AUTOSAR XML (schema 00046)
package /MICROSAR/NvM_swc/DataTypes
  impl type NvM_RequestResultType: compu {0=NVM_REQ_OK, 1=NVM_REQ_NOT_OK, 2=NVM_REQ_PENDING, 3=NVM_REQ_INTEGRITY_FAILED, 4=NVM_REQ_BLOCK_SKIPPED, 5=NVM_REQ_NV_INVALIDATED, 6=NVM_REQ_CANCELED, 7=NVM_REQ_REDUNDANCY_FAILED, 8=NVM_REQ_RESTORED_FROM_ROM}, range raw 0..8, implementation-data-type=uint8
  impl type NvM_BlockIdType: range raw 1..32767, implementation-data-type=uint16
  impl type NvM_ServiceIdType: compu {6=NVM_READ_BLOCK, 7=NVM_WRITE_BLOCK, 8=NVM_RESTORE_BLOCK_DEFAULTS, 9=NVM_ERASE_BLOCK, 11=NVM_INVALIDATE_NV_BLOCK, 12=NVM_READ_ALL}, range raw 6..12, implementation-data-type=uint8
package /MICROSAR/NvM_swc/Interfaces
  client server interface NvMAdministration: is-service=true, service-kind=NON-VOLATILE-RAM-MANAGER
    operation SetBlockProtection: possible-error=NvMAdministration/E_NOT_OK
      arg ProtectionEnabled: type=boolean, direction=IN
    error E_NOT_OK: error-code=1
  client server interface NvMService_AC3_SRBS_Defs: is-service=true, service-kind=NON-VOLATILE-RAM-MANAGER
    7 x operation, all with possible-error=NvMService_AC3_SRBS_Defs/E_NOT_OK:
      GetErrorStatus
        arg ErrorStatus: type=NvM_RequestResultType, direction=OUT
      SetRamBlockStatus
        arg RamBlockStatus: type=boolean, direction=IN
      ReadBlock
        arg DstPtr: type=dtRef_VOID, direction=IN
      WriteBlock
        arg SrcPtr: type=dtRef_const_VOID, direction=IN
      RestoreBlockDefaults
        arg DstPtr: type=dtRef_VOID, direction=IN
      InvalidateNvBlock
      EraseBlock
    error E_NOT_OK: error-code=1
  client server interface NvMNotifyJobFinished: is-service=true, service-kind=NON-VOLATILE-RAM-MANAGER
    operation JobFinished
      arg ServiceId: type=NvM_ServiceIdType, direction=IN
      arg JobResult: type=NvM_RequestResultType, direction=IN
package /MICROSAR/NvM_swc/ComponentTypes
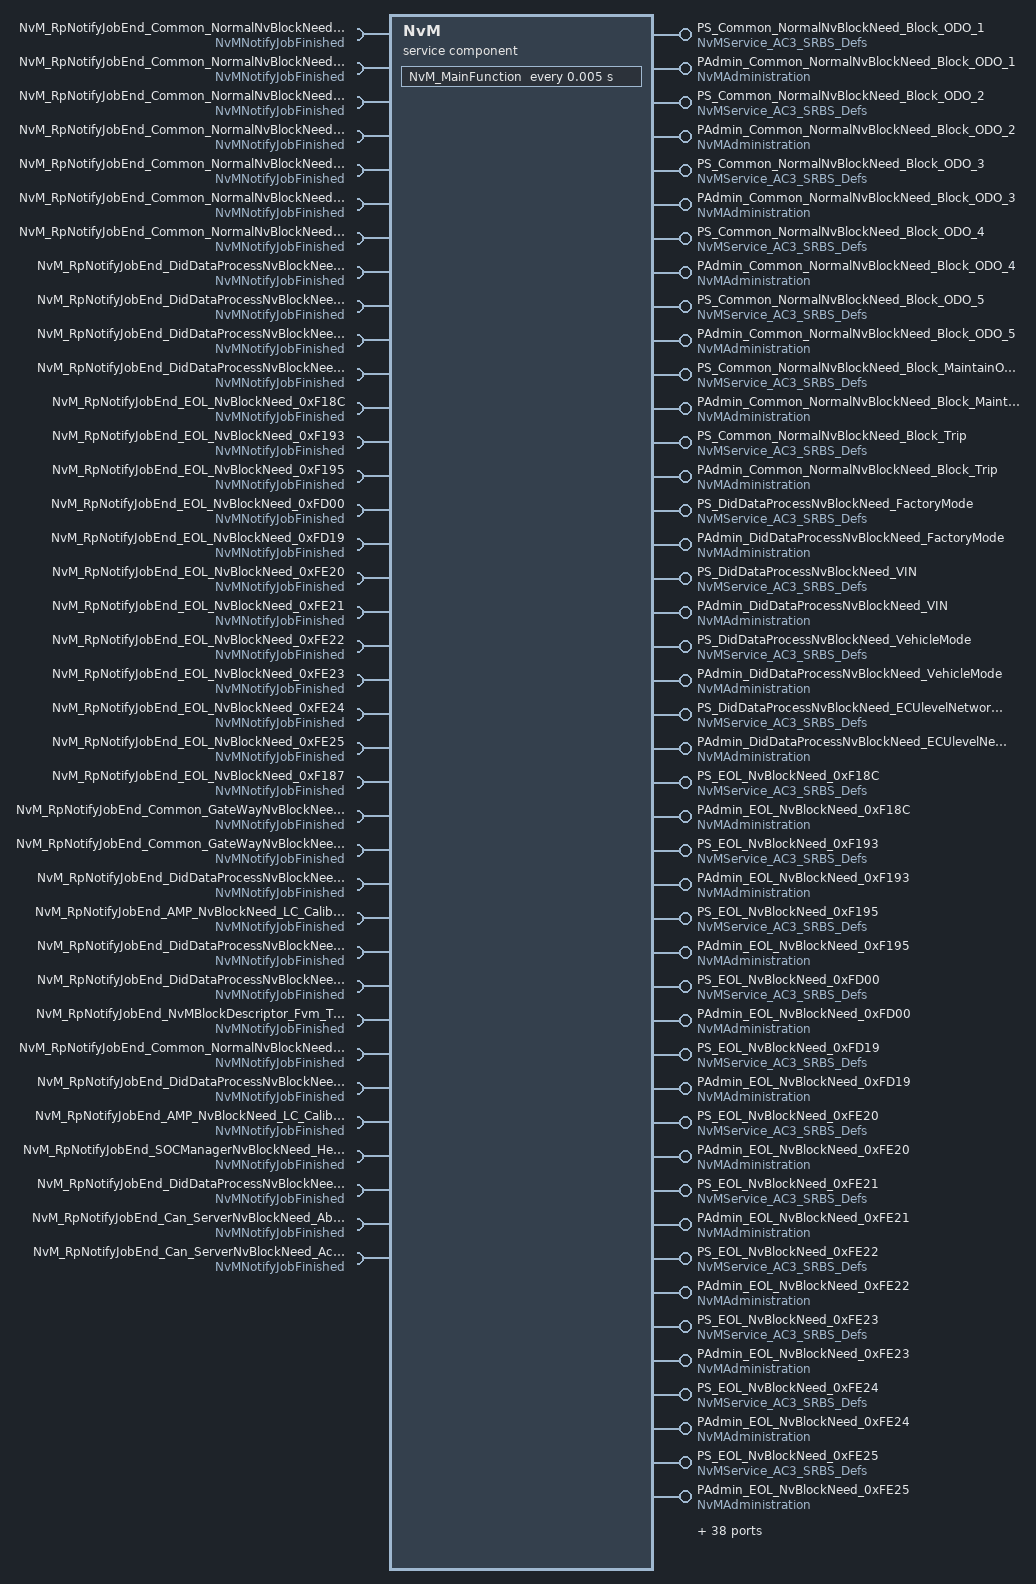
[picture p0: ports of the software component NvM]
  service sw component type NvM: category=SERVICE_COMPONENT
    provide port PS_Common_NormalNvBlockNeed_Block_ODO_1: provided-interface=NvMService_AC3_SRBS_Defs
    provide port PAdmin_Common_NormalNvBlockNeed_Block_ODO_1: provided-interface=NvMAdministration
    require port NvM_RpNotifyJobEnd_Common_NormalNvBlockNeed_Block_ODO_1: required-interface=NvMNotifyJobFinished
    provide port PS_Common_NormalNvBlockNeed_Block_ODO_2: provided-interface=NvMService_AC3_SRBS_Defs
    provide port PAdmin_Common_NormalNvBlockNeed_Block_ODO_2: provided-interface=NvMAdministration
    require port NvM_RpNotifyJobEnd_Common_NormalNvBlockNeed_Block_ODO_2: required-interface=NvMNotifyJobFinished
    provide port PS_Common_NormalNvBlockNeed_Block_ODO_3: provided-interface=NvMService_AC3_SRBS_Defs
    provide port PAdmin_Common_NormalNvBlockNeed_Block_ODO_3: provided-interface=NvMAdministration
    require port NvM_RpNotifyJobEnd_Common_NormalNvBlockNeed_Block_ODO_3: required-interface=NvMNotifyJobFinished
    provide port PS_Common_NormalNvBlockNeed_Block_ODO_4: provided-interface=NvMService_AC3_SRBS_Defs
    provide port PAdmin_Common_NormalNvBlockNeed_Block_ODO_4: provided-interface=NvMAdministration
    require port NvM_RpNotifyJobEnd_Common_NormalNvBlockNeed_Block_ODO_4: required-interface=NvMNotifyJobFinished
    provide port PS_Common_NormalNvBlockNeed_Block_ODO_5: provided-interface=NvMService_AC3_SRBS_Defs
    provide port PAdmin_Common_NormalNvBlockNeed_Block_ODO_5: provided-interface=NvMAdministration
    require port NvM_RpNotifyJobEnd_Common_NormalNvBlockNeed_Block_ODO_5: required-interface=NvMNotifyJobFinished
    provide port PS_Common_NormalNvBlockNeed_Block_MaintainOdo: provided-interface=NvMService_AC3_SRBS_Defs
    provide port PAdmin_Common_NormalNvBlockNeed_Block_MaintainOdo: provided-interface=NvMAdministration
    require port NvM_RpNotifyJobEnd_Common_NormalNvBlockNeed_Block_MaintainOdo: required-interface=NvMNotifyJobFinished
    provide port PS_Common_NormalNvBlockNeed_Block_Trip: provided-interface=NvMService_AC3_SRBS_Defs
    provide port PAdmin_Common_NormalNvBlockNeed_Block_Trip: provided-interface=NvMAdministration
    require port NvM_RpNotifyJobEnd_Common_NormalNvBlockNeed_Block_Trip: required-interface=NvMNotifyJobFinished
    provide port PS_DidDataProcessNvBlockNeed_FactoryMode: provided-interface=NvMService_AC3_SRBS_Defs
    provide port PAdmin_DidDataProcessNvBlockNeed_FactoryMode: provided-interface=NvMAdministration
    require port NvM_RpNotifyJobEnd_DidDataProcessNvBlockNeed_FactoryMode: required-interface=NvMNotifyJobFinished
    provide port PS_DidDataProcessNvBlockNeed_VIN: provided-interface=NvMService_AC3_SRBS_Defs
    provide port PAdmin_DidDataProcessNvBlockNeed_VIN: provided-interface=NvMAdministration
    require port NvM_RpNotifyJobEnd_DidDataProcessNvBlockNeed_VIN: required-interface=NvMNotifyJobFinished
    provide port PS_DidDataProcessNvBlockNeed_VehicleMode: provided-interface=NvMService_AC3_SRBS_Defs
    provide port PAdmin_DidDataProcessNvBlockNeed_VehicleMode: provided-interface=NvMAdministration
    require port NvM_RpNotifyJobEnd_DidDataProcessNvBlockNeed_VehicleMode: required-interface=NvMNotifyJobFinished
    provide port PS_DidDataProcessNvBlockNeed_ECUlevelNetworkConfigurationData: provided-interface=NvMService_AC3_SRBS_Defs
    provide port PAdmin_DidDataProcessNvBlockNeed_ECUlevelNetworkConfigurationData: provided-interface=NvMAdministration
    require port NvM_RpNotifyJobEnd_DidDataProcessNvBlockNeed_ECUlevelNetworkConfigurationData: required-interface=NvMNotifyJobFinished
    provide port PS_EOL_NvBlockNeed_0xF18C: provided-interface=NvMService_AC3_SRBS_Defs
    provide port PAdmin_EOL_NvBlockNeed_0xF18C: provided-interface=NvMAdministration
    require port NvM_RpNotifyJobEnd_EOL_NvBlockNeed_0xF18C: required-interface=NvMNotifyJobFinished
    provide port PS_EOL_NvBlockNeed_0xF193: provided-interface=NvMService_AC3_SRBS_Defs
    provide port PAdmin_EOL_NvBlockNeed_0xF193: provided-interface=NvMAdministration
    require port NvM_RpNotifyJobEnd_EOL_NvBlockNeed_0xF193: required-interface=NvMNotifyJobFinished
    provide port PS_EOL_NvBlockNeed_0xF195: provided-interface=NvMService_AC3_SRBS_Defs
    provide port PAdmin_EOL_NvBlockNeed_0xF195: provided-interface=NvMAdministration
    require port NvM_RpNotifyJobEnd_EOL_NvBlockNeed_0xF195: required-interface=NvMNotifyJobFinished
    provide port PS_EOL_NvBlockNeed_0xFD00: provided-interface=NvMService_AC3_SRBS_Defs
    provide port PAdmin_EOL_NvBlockNeed_0xFD00: provided-interface=NvMAdministration
    require port NvM_RpNotifyJobEnd_EOL_NvBlockNeed_0xFD00: required-interface=NvMNotifyJobFinished
    provide port PS_EOL_NvBlockNeed_0xFD19: provided-interface=NvMService_AC3_SRBS_Defs
    provide port PAdmin_EOL_NvBlockNeed_0xFD19: provided-interface=NvMAdministration
    require port NvM_RpNotifyJobEnd_EOL_NvBlockNeed_0xFD19: required-interface=NvMNotifyJobFinished
    provide port PS_EOL_NvBlockNeed_0xFE20: provided-interface=NvMService_AC3_SRBS_Defs
    provide port PAdmin_EOL_NvBlockNeed_0xFE20: provided-interface=NvMAdministration
    require port NvM_RpNotifyJobEnd_EOL_NvBlockNeed_0xFE20: required-interface=NvMNotifyJobFinished
    provide port PS_EOL_NvBlockNeed_0xFE21: provided-interface=NvMService_AC3_SRBS_Defs
    provide port PAdmin_EOL_NvBlockNeed_0xFE21: provided-interface=NvMAdministration
    require port NvM_RpNotifyJobEnd_EOL_NvBlockNeed_0xFE21: required-interface=NvMNotifyJobFinished
    provide port PS_EOL_NvBlockNeed_0xFE22: provided-interface=NvMService_AC3_SRBS_Defs
    provide port PAdmin_EOL_NvBlockNeed_0xFE22: provided-interface=NvMAdministration
    require port NvM_RpNotifyJobEnd_EOL_NvBlockNeed_0xFE22: required-interface=NvMNotifyJobFinished
    provide port PS_EOL_NvBlockNeed_0xFE23: provided-interface=NvMService_AC3_SRBS_Defs
    provide port PAdmin_EOL_NvBlockNeed_0xFE23: provided-interface=NvMAdministration
    require port NvM_RpNotifyJobEnd_EOL_NvBlockNeed_0xFE23: required-interface=NvMNotifyJobFinished
    provide port PS_EOL_NvBlockNeed_0xFE24: provided-interface=NvMService_AC3_SRBS_Defs
    provide port PAdmin_EOL_NvBlockNeed_0xFE24: provided-interface=NvMAdministration
    require port NvM_RpNotifyJobEnd_EOL_NvBlockNeed_0xFE24: required-interface=NvMNotifyJobFinished
    provide port PS_EOL_NvBlockNeed_0xFE25: provided-interface=NvMService_AC3_SRBS_Defs
    provide port PAdmin_EOL_NvBlockNeed_0xFE25: provided-interface=NvMAdministration
    require port NvM_RpNotifyJobEnd_EOL_NvBlockNeed_0xFE25: required-interface=NvMNotifyJobFinished
    provide port PS_EOL_NvBlockNeed_0xF187: provided-interface=NvMService_AC3_SRBS_Defs
    provide port PAdmin_EOL_NvBlockNeed_0xF187: provided-interface=NvMAdministration
    require port NvM_RpNotifyJobEnd_EOL_NvBlockNeed_0xF187: required-interface=NvMNotifyJobFinished
    provide port PS_Common_GateWayNvBlockNeed_Block_IPC_Config_Data: provided-interface=NvMService_AC3_SRBS_Defs
    provide port PAdmin_Common_GateWayNvBlockNeed_Block_IPC_Config_Data: provided-interface=NvMAdministration
    require port NvM_RpNotifyJobEnd_Common_GateWayNvBlockNeed_Block_IPC_Config_Data: required-interface=NvMNotifyJobFinished
    provide port PS_Common_GateWayNvBlockNeed_Block_IPC_CAN_Data: provided-interface=NvMService_AC3_SRBS_Defs
    provide port PAdmin_Common_GateWayNvBlockNeed_Block_IPC_CAN_Data: provided-interface=NvMAdministration
    require port NvM_RpNotifyJobEnd_Common_GateWayNvBlockNeed_Block_IPC_CAN_Data: required-interface=NvMNotifyJobFinished
    8 x provide port:
      PS_MiscNvBlockNeed_ResetInfomation: provided-interface=NvMService_AC3_SRBS_Defs
      PAdmin_MiscNvBlockNeed_ResetInfomation: provided-interface=NvMAdministration
      PS_DCM_ServerNvBlockNeedSecAttemptCount: provided-interface=NvMService_AC3_SRBS_Defs
      PAdmin_DCM_ServerNvBlockNeedSecAttemptCount: provided-interface=NvMAdministration
      PS_DCM_ServerNvBlockNeed_EOLUnlockCnt: provided-interface=NvMService_AC3_SRBS_Defs
      PAdmin_DCM_ServerNvBlockNeed_EOLUnlockCnt: provided-interface=NvMAdministration
      PS_DidDataProcessNvBlockNeed_ClusterInternalConfiguration: provided-interface=NvMService_AC3_SRBS_Defs
      PAdmin_DidDataProcessNvBlockNeed_ClusterInternalConfiguration: provided-interface=NvMAdministration
    require port NvM_RpNotifyJobEnd_DidDataProcessNvBlockNeed_ClusterInternalConfiguration: required-interface=NvMNotifyJobFinished
    provide port PS_AMP_NvBlockNeed_LC_Calibration: provided-interface=NvMService_AC3_SRBS_Defs
    provide port PAdmin_AMP_NvBlockNeed_LC_Calibration: provided-interface=NvMAdministration
    require port NvM_RpNotifyJobEnd_AMP_NvBlockNeed_LC_Calibration: required-interface=NvMNotifyJobFinished
    provide port PS_DidDataProcessNvBlockNeed_E2ESwitch: provided-interface=NvMService_AC3_SRBS_Defs
    provide port PAdmin_DidDataProcessNvBlockNeed_E2ESwitch: provided-interface=NvMAdministration
    require port NvM_RpNotifyJobEnd_DidDataProcessNvBlockNeed_E2ESwitch: required-interface=NvMNotifyJobFinished
    provide port PS_DidDataProcessNvBlockNeed_SecOcSwitch: provided-interface=NvMService_AC3_SRBS_Defs
    provide port PAdmin_DidDataProcessNvBlockNeed_SecOcSwitch: provided-interface=NvMAdministration
    require port NvM_RpNotifyJobEnd_DidDataProcessNvBlockNeed_SecOcSwitch: required-interface=NvMNotifyJobFinished
    4 x provide port:
      PS_NvBlockNeed_UpgradeResetFlag: provided-interface=NvMService_AC3_SRBS_Defs
      PAdmin_NvBlockNeed_UpgradeResetFlag: provided-interface=NvMAdministration
      PS_NvMBlockDescriptor_Fvm_TripCount: provided-interface=NvMService_AC3_SRBS_Defs
      PAdmin_NvMBlockDescriptor_Fvm_TripCount: provided-interface=NvMAdministration
    require port NvM_RpNotifyJobEnd_NvMBlockDescriptor_Fvm_TripCount: required-interface=NvMNotifyJobFinished
    provide port PS_Common_NormalNvBlockNeed_Menu: provided-interface=NvMService_AC3_SRBS_Defs
    provide port PAdmin_Common_NormalNvBlockNeed_Menu: provided-interface=NvMAdministration
    require port NvM_RpNotifyJobEnd_Common_NormalNvBlockNeed_Menu: required-interface=NvMNotifyJobFinished
    provide port PS_DidDataProcessNvBlockNeed_VehicleSoftwareVersion: provided-interface=NvMService_AC3_SRBS_Defs
    provide port PAdmin_DidDataProcessNvBlockNeed_VehicleSoftwareVersion: provided-interface=NvMAdministration
    require port NvM_RpNotifyJobEnd_DidDataProcessNvBlockNeed_VehicleSoftwareVersion: required-interface=NvMNotifyJobFinished
    provide port PS_AMP_NvBlockNeed_LC_Calibration2: provided-interface=NvMService_AC3_SRBS_Defs
    provide port PAdmin_AMP_NvBlockNeed_LC_Calibration2: provided-interface=NvMAdministration
    require port NvM_RpNotifyJobEnd_AMP_NvBlockNeed_LC_Calibration2: required-interface=NvMNotifyJobFinished
    provide port PS_SOCManagerNvBlockNeed_HealthSwitch: provided-interface=NvMService_AC3_SRBS_Defs
    provide port PAdmin_SOCManagerNvBlockNeed_HealthSwitch: provided-interface=NvMAdministration
    require port NvM_RpNotifyJobEnd_SOCManagerNvBlockNeed_HealthSwitch: required-interface=NvMNotifyJobFinished
    provide port PS_DidDataProcessNvBlockNeed_ClusterDisplayHMIAdjustmentOffset: provided-interface=NvMService_AC3_SRBS_Defs
    provide port PAdmin_DidDataProcessNvBlockNeed_ClusterDisplayHMIAdjustmentOffset: provided-interface=NvMAdministration
    require port NvM_RpNotifyJobEnd_DidDataProcessNvBlockNeed_ClusterDisplayHMIAdjustmentOffset: required-interface=NvMNotifyJobFinished
    provide port PS_Can_ServerNvBlockNeed_AbnormalWakeupSleepRecords: provided-interface=NvMService_AC3_SRBS_Defs
    provide port PAdmin_Can_ServerNvBlockNeed_AbnormalWakeupSleepRecords: provided-interface=NvMAdministration
    require port NvM_RpNotifyJobEnd_Can_ServerNvBlockNeed_AbnormalWakeupSleepRecords: required-interface=NvMNotifyJobFinished
    provide port PS_Can_ServerNvBlockNeed_ActiveWUCounter: provided-interface=NvMService_AC3_SRBS_Defs
    provide port PAdmin_Can_ServerNvBlockNeed_ActiveWUCounter: provided-interface=NvMAdministration
    require port NvM_RpNotifyJobEnd_Can_ServerNvBlockNeed_ActiveWUCounter: required-interface=NvMNotifyJobFinished
    behavior NvMInternalBehavior: handle-termination-and-restart=NO-SUPPORT
      timing event Timer_NvM_MainFunction: start-on-event=NvM_MainFunction, period=0.005
      328 x operation invoked event:
        OpEventGetErrorStatus_GetErrorStatus_PS_Common_NormalNvBlockNeed_Block_ODO_{1..5}: start-on-event=GetErrorStatus, operation=PS_Common_NormalNvBlockNeed_Block_ODO_{1..5}.GetErrorStatus
        OpEventGetErrorStatus_GetErrorStatus_PS_Common_NormalNvBlockNeed_Block_MaintainOdo: start-on-event=GetErrorStatus, operation=PS_Common_NormalNvBlockNeed_Block_MaintainOdo.GetErrorStatus
        OpEventGetErrorStatus_GetErrorStatus_PS_Common_NormalNvBlockNeed_Block_Trip: start-on-event=GetErrorStatus, operation=PS_Common_NormalNvBlockNeed_Block_Trip.GetErrorStatus
        OpEventSetRamBlockStatus_SetRamBlockStatus_PS_Common_NormalNvBlockNeed_Block_ODO_{1..5}: start-on-event=SetRamBlockStatus, operation=PS_Common_NormalNvBlockNeed_Block_ODO_{1..5}.SetRamBlockStatus
        OpEventSetRamBlockStatus_SetRamBlockStatus_PS_Common_NormalNvBlockNeed_Block_MaintainOdo: start-on-event=SetRamBlockStatus, operation=PS_Common_NormalNvBlockNeed_Block_MaintainOdo.SetRamBlockStatus
        OpEventSetRamBlockStatus_SetRamBlockStatus_PS_Common_NormalNvBlockNeed_Block_Trip: start-on-event=SetRamBlockStatus, operation=PS_Common_NormalNvBlockNeed_Block_Trip.SetRamBlockStatus
        OpEventReadBlock_ReadBlock_PS_Common_NormalNvBlockNeed_Block_ODO_{1..5}: start-on-event=ReadBlock, operation=PS_Common_NormalNvBlockNeed_Block_ODO_{1..5}.ReadBlock
        OpEventReadBlock_ReadBlock_PS_Common_NormalNvBlockNeed_Block_MaintainOdo: start-on-event=ReadBlock, operation=PS_Common_NormalNvBlockNeed_Block_MaintainOdo.ReadBlock
        OpEventReadBlock_ReadBlock_PS_Common_NormalNvBlockNeed_Block_Trip: start-on-event=ReadBlock, operation=PS_Common_NormalNvBlockNeed_Block_Trip.ReadBlock
        OpEventWriteBlock_WriteBlock_PS_Common_NormalNvBlockNeed_Block_ODO_{1..5}: start-on-event=WriteBlock, operation=PS_Common_NormalNvBlockNeed_Block_ODO_{1..5}.WriteBlock
        OpEventWriteBlock_WriteBlock_PS_Common_NormalNvBlockNeed_Block_MaintainOdo: start-on-event=WriteBlock, operation=PS_Common_NormalNvBlockNeed_Block_MaintainOdo.WriteBlock
        OpEventWriteBlock_WriteBlock_PS_Common_NormalNvBlockNeed_Block_Trip: start-on-event=WriteBlock, operation=PS_Common_NormalNvBlockNeed_Block_Trip.WriteBlock
        OpEventRestoreBlockDefaults_RestoreBlockDefaults_PS_Common_NormalNvBlockNeed_Block_ODO_{1..5}: start-on-event=RestoreBlockDefaults, operation=PS_Common_NormalNvBlockNeed_Block_ODO_{1..5}.RestoreBlockDefaults
        OpEventRestoreBlockDefaults_RestoreBlockDefaults_PS_Common_NormalNvBlockNeed_Block_MaintainOdo: start-on-event=RestoreBlockDefaults, operation=PS_Common_NormalNvBlockNeed_Block_MaintainOdo.RestoreBlockDefaults
        OpEventRestoreBlockDefaults_RestoreBlockDefaults_PS_Common_NormalNvBlockNeed_Block_Trip: start-on-event=RestoreBlockDefaults, operation=PS_Common_NormalNvBlockNeed_Block_Trip.RestoreBlockDefaults
        OpEventInvalidateNvBlock_InvalidateNvBlock_PS_Common_NormalNvBlockNeed_Block_ODO_{1..5}: start-on-event=InvalidateNvBlock, operation=PS_Common_NormalNvBlockNeed_Block_ODO_{1..5}.InvalidateNvBlock
        OpEventInvalidateNvBlock_InvalidateNvBlock_PS_Common_NormalNvBlockNeed_Block_MaintainOdo: start-on-event=InvalidateNvBlock, operation=PS_Common_NormalNvBlockNeed_Block_MaintainOdo.InvalidateNvBlock
        OpEventInvalidateNvBlock_InvalidateNvBlock_PS_Common_NormalNvBlockNeed_Block_Trip: start-on-event=InvalidateNvBlock, operation=PS_Common_NormalNvBlockNeed_Block_Trip.InvalidateNvBlock
        OpEventEraseBlock_EraseBlock_PS_Common_NormalNvBlockNeed_Block_ODO_{1..5}: start-on-event=EraseBlock, operation=PS_Common_NormalNvBlockNeed_Block_ODO_{1..5}.EraseBlock
        OpEventEraseBlock_EraseBlock_PS_Common_NormalNvBlockNeed_Block_MaintainOdo: start-on-event=EraseBlock, operation=PS_Common_NormalNvBlockNeed_Block_MaintainOdo.EraseBlock
        OpEventEraseBlock_EraseBlock_PS_Common_NormalNvBlockNeed_Block_Trip: start-on-event=EraseBlock, operation=PS_Common_NormalNvBlockNeed_Block_Trip.EraseBlock
        OpEventSetBlockProtection_SetBlockProtection_PAdmin_Common_NormalNvBlockNeed_Block_ODO_{1..5}: start-on-event=SetBlockProtection, operation=PAdmin_Common_NormalNvBlockNeed_Block_ODO_{1..5}.SetBlockProtection
        OpEventSetBlockProtection_SetBlockProtection_PAdmin_Common_NormalNvBlockNeed_Block_MaintainOdo: start-on-event=SetBlockProtection, operation=PAdmin_Common_NormalNvBlockNeed_Block_MaintainOdo.SetBlockProtection
        OpEventSetBlockProtection_SetBlockProtection_PAdmin_Common_NormalNvBlockNeed_Block_Trip: start-on-event=SetBlockProtection, operation=PAdmin_Common_NormalNvBlockNeed_Block_Trip.SetBlockProtection
        OpEventGetErrorStatus_GetErrorStatus_PS_DidDataProcessNvBlockNeed_FactoryMode: start-on-event=GetErrorStatus, operation=PS_DidDataProcessNvBlockNeed_FactoryMode.GetErrorStatus
        OpEventGetErrorStatus_GetErrorStatus_PS_DidDataProcessNvBlockNeed_VIN: start-on-event=GetErrorStatus, operation=PS_DidDataProcessNvBlockNeed_VIN.GetErrorStatus
        OpEventGetErrorStatus_GetErrorStatus_PS_DidDataProcessNvBlockNeed_VehicleMode: start-on-event=GetErrorStatus, operation=PS_DidDataProcessNvBlockNeed_VehicleMode.GetErrorStatus
        OpEventSetRamBlockStatus_SetRamBlockStatus_PS_DidDataProcessNvBlockNeed_FactoryMode: start-on-event=SetRamBlockStatus, operation=PS_DidDataProcessNvBlockNeed_FactoryMode.SetRamBlockStatus
        OpEventSetRamBlockStatus_SetRamBlockStatus_PS_DidDataProcessNvBlockNeed_VIN: start-on-event=SetRamBlockStatus, operation=PS_DidDataProcessNvBlockNeed_VIN.SetRamBlockStatus
        OpEventSetRamBlockStatus_SetRamBlockStatus_PS_DidDataProcessNvBlockNeed_VehicleMode: start-on-event=SetRamBlockStatus, operation=PS_DidDataProcessNvBlockNeed_VehicleMode.SetRamBlockStatus
        OpEventReadBlock_ReadBlock_PS_DidDataProcessNvBlockNeed_FactoryMode: start-on-event=ReadBlock, operation=PS_DidDataProcessNvBlockNeed_FactoryMode.ReadBlock
        OpEventReadBlock_ReadBlock_PS_DidDataProcessNvBlockNeed_VIN: start-on-event=ReadBlock, operation=PS_DidDataProcessNvBlockNeed_VIN.ReadBlock
        OpEventReadBlock_ReadBlock_PS_DidDataProcessNvBlockNeed_VehicleMode: start-on-event=ReadBlock, operation=PS_DidDataProcessNvBlockNeed_VehicleMode.ReadBlock
        OpEventWriteBlock_WriteBlock_PS_DidDataProcessNvBlockNeed_FactoryMode: start-on-event=WriteBlock, operation=PS_DidDataProcessNvBlockNeed_FactoryMode.WriteBlock
        OpEventWriteBlock_WriteBlock_PS_DidDataProcessNvBlockNeed_VIN: start-on-event=WriteBlock, operation=PS_DidDataProcessNvBlockNeed_VIN.WriteBlock
        OpEventWriteBlock_WriteBlock_PS_DidDataProcessNvBlockNeed_VehicleMode: start-on-event=WriteBlock, operation=PS_DidDataProcessNvBlockNeed_VehicleMode.WriteBlock
        OpEventRestoreBlockDefaults_RestoreBlockDefaults_PS_DidDataProcessNvBlockNeed_FactoryMode: start-on-event=RestoreBlockDefaults, operation=PS_DidDataProcessNvBlockNeed_FactoryMode.RestoreBlockDefaults
        OpEventRestoreBlockDefaults_RestoreBlockDefaults_PS_DidDataProcessNvBlockNeed_VIN: start-on-event=RestoreBlockDefaults, operation=PS_DidDataProcessNvBlockNeed_VIN.RestoreBlockDefaults
        OpEventRestoreBlockDefaults_RestoreBlockDefaults_PS_DidDataProcessNvBlockNeed_VehicleMode: start-on-event=RestoreBlockDefaults, operation=PS_DidDataProcessNvBlockNeed_VehicleMode.RestoreBlockDefaults
        OpEventInvalidateNvBlock_InvalidateNvBlock_PS_DidDataProcessNvBlockNeed_FactoryMode: start-on-event=InvalidateNvBlock, operation=PS_DidDataProcessNvBlockNeed_FactoryMode.InvalidateNvBlock
        OpEventInvalidateNvBlock_InvalidateNvBlock_PS_DidDataProcessNvBlockNeed_VIN: start-on-event=InvalidateNvBlock, operation=PS_DidDataProcessNvBlockNeed_VIN.InvalidateNvBlock
        OpEventInvalidateNvBlock_InvalidateNvBlock_PS_DidDataProcessNvBlockNeed_VehicleMode: start-on-event=InvalidateNvBlock, operation=PS_DidDataProcessNvBlockNeed_VehicleMode.InvalidateNvBlock
        OpEventEraseBlock_EraseBlock_PS_DidDataProcessNvBlockNeed_FactoryMode: start-on-event=EraseBlock, operation=PS_DidDataProcessNvBlockNeed_FactoryMode.EraseBlock
        OpEventEraseBlock_EraseBlock_PS_DidDataProcessNvBlockNeed_VIN: start-on-event=EraseBlock, operation=PS_DidDataProcessNvBlockNeed_VIN.EraseBlock
        OpEventEraseBlock_EraseBlock_PS_DidDataProcessNvBlockNeed_VehicleMode: start-on-event=EraseBlock, operation=PS_DidDataProcessNvBlockNeed_VehicleMode.EraseBlock
        OpEventSetBlockProtection_SetBlockProtection_PAdmin_DidDataProcessNvBlockNeed_FactoryMode: start-on-event=SetBlockProtection, operation=PAdmin_DidDataProcessNvBlockNeed_FactoryMode.SetBlockProtection
        OpEventSetBlockProtection_SetBlockProtection_PAdmin_DidDataProcessNvBlockNeed_VIN: start-on-event=SetBlockProtection, operation=PAdmin_DidDataProcessNvBlockNeed_VIN.SetBlockProtection
        OpEventSetBlockProtection_SetBlockProtection_PAdmin_DidDataProcessNvBlockNeed_VehicleMode: start-on-event=SetBlockProtection, operation=PAdmin_DidDataProcessNvBlockNeed_VehicleMode.SetBlockProtection
        OpEventGetErrorStatus_GetErrorStatus_PS_DidDataProcessNvBlockNeed_ECUlevelNetworkConfigurationData: start-on-event=GetErrorStatus, operation=PS_DidDataProcessNvBlockNeed_ECUlevelNetworkConfigurationData.GetErrorStatus
        OpEventSetRamBlockStatus_SetRamBlockStatus_PS_DidDataProcessNvBlockNeed_ECUlevelNetworkConfigurationData: start-on-event=SetRamBlockStatus, operation=PS_DidDataProcessNvBlockNeed_ECUlevelNetworkConfigurationData.SetRamBlockStatus
        OpEventReadBlock_ReadBlock_PS_DidDataProcessNvBlockNeed_ECUlevelNetworkConfigurationData: start-on-event=ReadBlock, operation=PS_DidDataProcessNvBlockNeed_ECUlevelNetworkConfigurationData.ReadBlock
        OpEventWriteBlock_WriteBlock_PS_DidDataProcessNvBlockNeed_ECUlevelNetworkConfigurationData: start-on-event=WriteBlock, operation=PS_DidDataProcessNvBlockNeed_ECUlevelNetworkConfigurationData.WriteBlock
        OpEventRestoreBlockDefaults_RestoreBlockDefaults_PS_DidDataProcessNvBlockNeed_ECUlevelNetworkConfigurationData: start-on-event=RestoreBlockDefaults, operation=PS_DidDataProcessNvBlockNeed_ECUlevelNetworkConfigurationData.RestoreBlockDefaults
        OpEventInvalidateNvBlock_InvalidateNvBlock_PS_DidDataProcessNvBlockNeed_ECUlevelNetworkConfigurationData: start-on-event=InvalidateNvBlock, operation=PS_DidDataProcessNvBlockNeed_ECUlevelNetworkConfigurationData.InvalidateNvBlock
        OpEventEraseBlock_EraseBlock_PS_DidDataProcessNvBlockNeed_ECUlevelNetworkConfigurationData: start-on-event=EraseBlock, operation=PS_DidDataProcessNvBlockNeed_ECUlevelNetworkConfigurationData.EraseBlock
        OpEventSetBlockProtection_SetBlockProtection_PAdmin_DidDataProcessNvBlockNeed_ECUlevelNetworkConfigurationData: start-on-event=SetBlockProtection, operation=PAdmin_DidDataProcessNvBlockNeed_ECUlevelNetworkConfigurationData.SetBlockProtection
        OpEventGetErrorStatus_GetErrorStatus_PS_EOL_NvBlockNeed_0xF18C: start-on-event=GetErrorStatus, operation=PS_EOL_NvBlockNeed_0xF18C.GetErrorStatus
        OpEventSetRamBlockStatus_SetRamBlockStatus_PS_EOL_NvBlockNeed_0xF18C: start-on-event=SetRamBlockStatus, operation=PS_EOL_NvBlockNeed_0xF18C.SetRamBlockStatus
        OpEventReadBlock_ReadBlock_PS_EOL_NvBlockNeed_0xF18C: start-on-event=ReadBlock, operation=PS_EOL_NvBlockNeed_0xF18C.ReadBlock
        OpEventWriteBlock_WriteBlock_PS_EOL_NvBlockNeed_0xF18C: start-on-event=WriteBlock, operation=PS_EOL_NvBlockNeed_0xF18C.WriteBlock
        OpEventRestoreBlockDefaults_RestoreBlockDefaults_PS_EOL_NvBlockNeed_0xF18C: start-on-event=RestoreBlockDefaults, operation=PS_EOL_NvBlockNeed_0xF18C.RestoreBlockDefaults
        OpEventInvalidateNvBlock_InvalidateNvBlock_PS_EOL_NvBlockNeed_0xF18C: start-on-event=InvalidateNvBlock, operation=PS_EOL_NvBlockNeed_0xF18C.InvalidateNvBlock
        OpEventEraseBlock_EraseBlock_PS_EOL_NvBlockNeed_0xF18C: start-on-event=EraseBlock, operation=PS_EOL_NvBlockNeed_0xF18C.EraseBlock
        OpEventSetBlockProtection_SetBlockProtection_PAdmin_EOL_NvBlockNeed_0xF18C: start-on-event=SetBlockProtection, operation=PAdmin_EOL_NvBlockNeed_0xF18C.SetBlockProtection
        OpEventGetErrorStatus_GetErrorStatus_PS_EOL_NvBlockNeed_0xF193: start-on-event=GetErrorStatus, operation=PS_EOL_NvBlockNeed_0xF193.GetErrorStatus
        OpEventGetErrorStatus_GetErrorStatus_PS_EOL_NvBlockNeed_0xF195: start-on-event=GetErrorStatus, operation=PS_EOL_NvBlockNeed_0xF195.GetErrorStatus
        OpEventGetErrorStatus_GetErrorStatus_PS_EOL_NvBlockNeed_0xFD00: start-on-event=GetErrorStatus, operation=PS_EOL_NvBlockNeed_0xFD00.GetErrorStatus
        OpEventSetRamBlockStatus_SetRamBlockStatus_PS_EOL_NvBlockNeed_0xF193: start-on-event=SetRamBlockStatus, operation=PS_EOL_NvBlockNeed_0xF193.SetRamBlockStatus
        OpEventSetRamBlockStatus_SetRamBlockStatus_PS_EOL_NvBlockNeed_0xF195: start-on-event=SetRamBlockStatus, operation=PS_EOL_NvBlockNeed_0xF195.SetRamBlockStatus
        OpEventSetRamBlockStatus_SetRamBlockStatus_PS_EOL_NvBlockNeed_0xFD00: start-on-event=SetRamBlockStatus, operation=PS_EOL_NvBlockNeed_0xFD00.SetRamBlockStatus
        OpEventReadBlock_ReadBlock_PS_EOL_NvBlockNeed_0xF193: start-on-event=ReadBlock, operation=PS_EOL_NvBlockNeed_0xF193.ReadBlock
        OpEventReadBlock_ReadBlock_PS_EOL_NvBlockNeed_0xF195: start-on-event=ReadBlock, operation=PS_EOL_NvBlockNeed_0xF195.ReadBlock
        OpEventReadBlock_ReadBlock_PS_EOL_NvBlockNeed_0xFD00: start-on-event=ReadBlock, operation=PS_EOL_NvBlockNeed_0xFD00.ReadBlock
        OpEventWriteBlock_WriteBlock_PS_EOL_NvBlockNeed_0xF193: start-on-event=WriteBlock, operation=PS_EOL_NvBlockNeed_0xF193.WriteBlock
        OpEventWriteBlock_WriteBlock_PS_EOL_NvBlockNeed_0xF195: start-on-event=WriteBlock, operation=PS_EOL_NvBlockNeed_0xF195.WriteBlock
        OpEventWriteBlock_WriteBlock_PS_EOL_NvBlockNeed_0xFD00: start-on-event=WriteBlock, operation=PS_EOL_NvBlockNeed_0xFD00.WriteBlock
        OpEventRestoreBlockDefaults_RestoreBlockDefaults_PS_EOL_NvBlockNeed_0xF193: start-on-event=RestoreBlockDefaults, operation=PS_EOL_NvBlockNeed_0xF193.RestoreBlockDefaults
        OpEventRestoreBlockDefaults_RestoreBlockDefaults_PS_EOL_NvBlockNeed_0xF195: start-on-event=RestoreBlockDefaults, operation=PS_EOL_NvBlockNeed_0xF195.RestoreBlockDefaults
        OpEventRestoreBlockDefaults_RestoreBlockDefaults_PS_EOL_NvBlockNeed_0xFD00: start-on-event=RestoreBlockDefaults, operation=PS_EOL_NvBlockNeed_0xFD00.RestoreBlockDefaults
        OpEventInvalidateNvBlock_InvalidateNvBlock_PS_EOL_NvBlockNeed_0xF193: start-on-event=InvalidateNvBlock, operation=PS_EOL_NvBlockNeed_0xF193.InvalidateNvBlock
        OpEventInvalidateNvBlock_InvalidateNvBlock_PS_EOL_NvBlockNeed_0xF195: start-on-event=InvalidateNvBlock, operation=PS_EOL_NvBlockNeed_0xF195.InvalidateNvBlock
        OpEventInvalidateNvBlock_InvalidateNvBlock_PS_EOL_NvBlockNeed_0xFD00: start-on-event=InvalidateNvBlock, operation=PS_EOL_NvBlockNeed_0xFD00.InvalidateNvBlock
        OpEventEraseBlock_EraseBlock_PS_EOL_NvBlockNeed_0xF193: start-on-event=EraseBlock, operation=PS_EOL_NvBlockNeed_0xF193.EraseBlock
        OpEventEraseBlock_EraseBlock_PS_EOL_NvBlockNeed_0xF195: start-on-event=EraseBlock, operation=PS_EOL_NvBlockNeed_0xF195.EraseBlock
        OpEventEraseBlock_EraseBlock_PS_EOL_NvBlockNeed_0xFD00: start-on-event=EraseBlock, operation=PS_EOL_NvBlockNeed_0xFD00.EraseBlock
        OpEventSetBlockProtection_SetBlockProtection_PAdmin_EOL_NvBlockNeed_0xF193: start-on-event=SetBlockProtection, operation=PAdmin_EOL_NvBlockNeed_0xF193.SetBlockProtection
        OpEventSetBlockProtection_SetBlockProtection_PAdmin_EOL_NvBlockNeed_0xF195: start-on-event=SetBlockProtection, operation=PAdmin_EOL_NvBlockNeed_0xF195.SetBlockProtection
        OpEventSetBlockProtection_SetBlockProtection_PAdmin_EOL_NvBlockNeed_0xFD00: start-on-event=SetBlockProtection, operation=PAdmin_EOL_NvBlockNeed_0xFD00.SetBlockProtection
        OpEventGetErrorStatus_GetErrorStatus_PS_EOL_NvBlockNeed_0xFD19: start-on-event=GetErrorStatus, operation=PS_EOL_NvBlockNeed_0xFD19.GetErrorStatus
        OpEventSetRamBlockStatus_SetRamBlockStatus_PS_EOL_NvBlockNeed_0xFD19: start-on-event=SetRamBlockStatus, operation=PS_EOL_NvBlockNeed_0xFD19.SetRamBlockStatus
        OpEventReadBlock_ReadBlock_PS_EOL_NvBlockNeed_0xFD19: start-on-event=ReadBlock, operation=PS_EOL_NvBlockNeed_0xFD19.ReadBlock
        OpEventWriteBlock_WriteBlock_PS_EOL_NvBlockNeed_0xFD19: start-on-event=WriteBlock, operation=PS_EOL_NvBlockNeed_0xFD19.WriteBlock
        OpEventRestoreBlockDefaults_RestoreBlockDefaults_PS_EOL_NvBlockNeed_0xFD19: start-on-event=RestoreBlockDefaults, operation=PS_EOL_NvBlockNeed_0xFD19.RestoreBlockDefaults
        OpEventInvalidateNvBlock_InvalidateNvBlock_PS_EOL_NvBlockNeed_0xFD19: start-on-event=InvalidateNvBlock, operation=PS_EOL_NvBlockNeed_0xFD19.InvalidateNvBlock
        OpEventEraseBlock_EraseBlock_PS_EOL_NvBlockNeed_0xFD19: start-on-event=EraseBlock, operation=PS_EOL_NvBlockNeed_0xFD19.EraseBlock
        OpEventSetBlockProtection_SetBlockProtection_PAdmin_EOL_NvBlockNeed_0xFD19: start-on-event=SetBlockProtection, operation=PAdmin_EOL_NvBlockNeed_0xFD19.SetBlockProtection
        OpEventGetErrorStatus_GetErrorStatus_PS_EOL_NvBlockNeed_0xFE{20..25}: start-on-event=GetErrorStatus, operation=PS_EOL_NvBlockNeed_0xFE{20..25}.GetErrorStatus
        OpEventSetRamBlockStatus_SetRamBlockStatus_PS_EOL_NvBlockNeed_0xFE{20..25}: start-on-event=SetRamBlockStatus, operation=PS_EOL_NvBlockNeed_0xFE{20..25}.SetRamBlockStatus
        OpEventReadBlock_ReadBlock_PS_EOL_NvBlockNeed_0xFE{20..25}: start-on-event=ReadBlock, operation=PS_EOL_NvBlockNeed_0xFE{20..25}.ReadBlock
        OpEventWriteBlock_WriteBlock_PS_EOL_NvBlockNeed_0xFE{20..25}: start-on-event=WriteBlock, operation=PS_EOL_NvBlockNeed_0xFE{20..25}.WriteBlock
        OpEventRestoreBlockDefaults_RestoreBlockDefaults_PS_EOL_NvBlockNeed_0xFE{20..25}: start-on-event=RestoreBlockDefaults, operation=PS_EOL_NvBlockNeed_0xFE{20..25}.RestoreBlockDefaults
        OpEventInvalidateNvBlock_InvalidateNvBlock_PS_EOL_NvBlockNeed_0xFE{20..25}: start-on-event=InvalidateNvBlock, operation=PS_EOL_NvBlockNeed_0xFE{20..25}.InvalidateNvBlock
        OpEventEraseBlock_EraseBlock_PS_EOL_NvBlockNeed_0xFE{20..25}: start-on-event=EraseBlock, operation=PS_EOL_NvBlockNeed_0xFE{20..25}.EraseBlock
        OpEventSetBlockProtection_SetBlockProtection_PAdmin_EOL_NvBlockNeed_0xFE{20..25}: start-on-event=SetBlockProtection, operation=PAdmin_EOL_NvBlockNeed_0xFE{20..25}.SetBlockProtection
        OpEventGetErrorStatus_GetErrorStatus_PS_EOL_NvBlockNeed_0xF187: start-on-event=GetErrorStatus, operation=PS_EOL_NvBlockNeed_0xF187.GetErrorStatus
        OpEventSetRamBlockStatus_SetRamBlockStatus_PS_EOL_NvBlockNeed_0xF187: start-on-event=SetRamBlockStatus, operation=PS_EOL_NvBlockNeed_0xF187.SetRamBlockStatus
        OpEventReadBlock_ReadBlock_PS_EOL_NvBlockNeed_0xF187: start-on-event=ReadBlock, operation=PS_EOL_NvBlockNeed_0xF187.ReadBlock
        OpEventWriteBlock_WriteBlock_PS_EOL_NvBlockNeed_0xF187: start-on-event=WriteBlock, operation=PS_EOL_NvBlockNeed_0xF187.WriteBlock
        OpEventRestoreBlockDefaults_RestoreBlockDefaults_PS_EOL_NvBlockNeed_0xF187: start-on-event=RestoreBlockDefaults, operation=PS_EOL_NvBlockNeed_0xF187.RestoreBlockDefaults
        OpEventInvalidateNvBlock_InvalidateNvBlock_PS_EOL_NvBlockNeed_0xF187: start-on-event=InvalidateNvBlock, operation=PS_EOL_NvBlockNeed_0xF187.InvalidateNvBlock
        OpEventEraseBlock_EraseBlock_PS_EOL_NvBlockNeed_0xF187: start-on-event=EraseBlock, operation=PS_EOL_NvBlockNeed_0xF187.EraseBlock
        OpEventSetBlockProtection_SetBlockProtection_PAdmin_EOL_NvBlockNeed_0xF187: start-on-event=SetBlockProtection, operation=PAdmin_EOL_NvBlockNeed_0xF187.SetBlockProtection
        OpEventGetErrorStatus_GetErrorStatus_PS_Common_GateWayNvBlockNeed_Block_IPC_Config_Data: start-on-event=GetErrorStatus, operation=PS_Common_GateWayNvBlockNeed_Block_IPC_Config_Data.GetErrorStatus
        OpEventGetErrorStatus_GetErrorStatus_PS_Common_GateWayNvBlockNeed_Block_IPC_CAN_Data: start-on-event=GetErrorStatus, operation=PS_Common_GateWayNvBlockNeed_Block_IPC_CAN_Data.GetErrorStatus
        OpEventSetRamBlockStatus_SetRamBlockStatus_PS_Common_GateWayNvBlockNeed_Block_IPC_Config_Data: start-on-event=SetRamBlockStatus, operation=PS_Common_GateWayNvBlockNeed_Block_IPC_Config_Data.SetRamBlockStatus
        OpEventSetRamBlockStatus_SetRamBlockStatus_PS_Common_GateWayNvBlockNeed_Block_IPC_CAN_Data: start-on-event=SetRamBlockStatus, operation=PS_Common_GateWayNvBlockNeed_Block_IPC_CAN_Data.SetRamBlockStatus
        OpEventReadBlock_ReadBlock_PS_Common_GateWayNvBlockNeed_Block_IPC_Config_Data: start-on-event=ReadBlock, operation=PS_Common_GateWayNvBlockNeed_Block_IPC_Config_Data.ReadBlock
        OpEventReadBlock_ReadBlock_PS_Common_GateWayNvBlockNeed_Block_IPC_CAN_Data: start-on-event=ReadBlock, operation=PS_Common_GateWayNvBlockNeed_Block_IPC_CAN_Data.ReadBlock
        OpEventWriteBlock_WriteBlock_PS_Common_GateWayNvBlockNeed_Block_IPC_Config_Data: start-on-event=WriteBlock, operation=PS_Common_GateWayNvBlockNeed_Block_IPC_Config_Data.WriteBlock
        OpEventWriteBlock_WriteBlock_PS_Common_GateWayNvBlockNeed_Block_IPC_CAN_Data: start-on-event=WriteBlock, operation=PS_Common_GateWayNvBlockNeed_Block_IPC_CAN_Data.WriteBlock
        OpEventRestoreBlockDefaults_RestoreBlockDefaults_PS_Common_GateWayNvBlockNeed_Block_IPC_Config_Data: start-on-event=RestoreBlockDefaults, operation=PS_Common_GateWayNvBlockNeed_Block_IPC_Config_Data.RestoreBlockDefaults
        OpEventRestoreBlockDefaults_RestoreBlockDefaults_PS_Common_GateWayNvBlockNeed_Block_IPC_CAN_Data: start-on-event=RestoreBlockDefaults, operation=PS_Common_GateWayNvBlockNeed_Block_IPC_CAN_Data.RestoreBlockDefaults
        OpEventInvalidateNvBlock_InvalidateNvBlock_PS_Common_GateWayNvBlockNeed_Block_IPC_Config_Data: start-on-event=InvalidateNvBlock, operation=PS_Common_GateWayNvBlockNeed_Block_IPC_Config_Data.InvalidateNvBlock
        OpEventInvalidateNvBlock_InvalidateNvBlock_PS_Common_GateWayNvBlockNeed_Block_IPC_CAN_Data: start-on-event=InvalidateNvBlock, operation=PS_Common_GateWayNvBlockNeed_Block_IPC_CAN_Data.InvalidateNvBlock
        OpEventEraseBlock_EraseBlock_PS_Common_GateWayNvBlockNeed_Block_IPC_Config_Data: start-on-event=EraseBlock, operation=PS_Common_GateWayNvBlockNeed_Block_IPC_Config_Data.EraseBlock
        OpEventEraseBlock_EraseBlock_PS_Common_GateWayNvBlockNeed_Block_IPC_CAN_Data: start-on-event=EraseBlock, operation=PS_Common_GateWayNvBlockNeed_Block_IPC_CAN_Data.EraseBlock
        OpEventSetBlockProtection_SetBlockProtection_PAdmin_Common_GateWayNvBlockNeed_Block_IPC_Config_Data: start-on-event=SetBlockProtection, operation=PAdmin_Common_GateWayNvBlockNeed_Block_IPC_Config_Data.SetBlockProtection
        OpEventSetBlockProtection_SetBlockProtection_PAdmin_Common_GateWayNvBlockNeed_Block_IPC_CAN_Data: start-on-event=SetBlockProtection, operation=PAdmin_Common_GateWayNvBlockNeed_Block_IPC_CAN_Data.SetBlockProtection
        OpEventGetErrorStatus_GetErrorStatus_PS_MiscNvBlockNeed_ResetInfomation: start-on-event=GetErrorStatus, operation=PS_MiscNvBlockNeed_ResetInfomation.GetErrorStatus
        OpEventSetRamBlockStatus_SetRamBlockStatus_PS_MiscNvBlockNeed_ResetInfomation: start-on-event=SetRamBlockStatus, operation=PS_MiscNvBlockNeed_ResetInfomation.SetRamBlockStatus
        OpEventReadBlock_ReadBlock_PS_MiscNvBlockNeed_ResetInfomation: start-on-event=ReadBlock, operation=PS_MiscNvBlockNeed_ResetInfomation.ReadBlock
        OpEventWriteBlock_WriteBlock_PS_MiscNvBlockNeed_ResetInfomation: start-on-event=WriteBlock, operation=PS_MiscNvBlockNeed_ResetInfomation.WriteBlock
        OpEventRestoreBlockDefaults_RestoreBlockDefaults_PS_MiscNvBlockNeed_ResetInfomation: start-on-event=RestoreBlockDefaults, operation=PS_MiscNvBlockNeed_ResetInfomation.RestoreBlockDefaults
        OpEventInvalidateNvBlock_InvalidateNvBlock_PS_MiscNvBlockNeed_ResetInfomation: start-on-event=InvalidateNvBlock, operation=PS_MiscNvBlockNeed_ResetInfomation.InvalidateNvBlock
        OpEventEraseBlock_EraseBlock_PS_MiscNvBlockNeed_ResetInfomation: start-on-event=EraseBlock, operation=PS_MiscNvBlockNeed_ResetInfomation.EraseBlock
        OpEventSetBlockProtection_SetBlockProtection_PAdmin_MiscNvBlockNeed_ResetInfomation: start-on-event=SetBlockProtection, operation=PAdmin_MiscNvBlockNeed_ResetInfomation.SetBlockProtection
        OpEventGetErrorStatus_GetErrorStatus_PS_DCM_ServerNvBlockNeedSecAttemptCount: start-on-event=GetErrorStatus, operation=PS_DCM_ServerNvBlockNeedSecAttemptCount.GetErrorStatus
        OpEventSetRamBlockStatus_SetRamBlockStatus_PS_DCM_ServerNvBlockNeedSecAttemptCount: start-on-event=SetRamBlockStatus, operation=PS_DCM_ServerNvBlockNeedSecAttemptCount.SetRamBlockStatus
        OpEventReadBlock_ReadBlock_PS_DCM_ServerNvBlockNeedSecAttemptCount: start-on-event=ReadBlock, operation=PS_DCM_ServerNvBlockNeedSecAttemptCount.ReadBlock
        OpEventWriteBlock_WriteBlock_PS_DCM_ServerNvBlockNeedSecAttemptCount: start-on-event=WriteBlock, operation=PS_DCM_ServerNvBlockNeedSecAttemptCount.WriteBlock
        OpEventInvalidateNvBlock_InvalidateNvBlock_PS_DCM_ServerNvBlockNeedSecAttemptCount: start-on-event=InvalidateNvBlock, operation=PS_DCM_ServerNvBlockNeedSecAttemptCount.InvalidateNvBlock
        OpEventEraseBlock_EraseBlock_PS_DCM_ServerNvBlockNeedSecAttemptCount: start-on-event=EraseBlock, operation=PS_DCM_ServerNvBlockNeedSecAttemptCount.EraseBlock
        OpEventSetBlockProtection_SetBlockProtection_PAdmin_DCM_ServerNvBlockNeedSecAttemptCount: start-on-event=SetBlockProtection, operation=PAdmin_DCM_ServerNvBlockNeedSecAttemptCount.SetBlockProtection
        OpEventGetErrorStatus_GetErrorStatus_PS_DCM_ServerNvBlockNeed_EOLUnlockCnt: start-on-event=GetErrorStatus, operation=PS_DCM_ServerNvBlockNeed_EOLUnlockCnt.GetErrorStatus
        OpEventSetRamBlockStatus_SetRamBlockStatus_PS_DCM_ServerNvBlockNeed_EOLUnlockCnt: start-on-event=SetRamBlockStatus, operation=PS_DCM_ServerNvBlockNeed_EOLUnlockCnt.SetRamBlockStatus
        OpEventReadBlock_ReadBlock_PS_DCM_ServerNvBlockNeed_EOLUnlockCnt: start-on-event=ReadBlock, operation=PS_DCM_ServerNvBlockNeed_EOLUnlockCnt.ReadBlock
        OpEventWriteBlock_WriteBlock_PS_DCM_ServerNvBlockNeed_EOLUnlockCnt: start-on-event=WriteBlock, operation=PS_DCM_ServerNvBlockNeed_EOLUnlockCnt.WriteBlock
        OpEventInvalidateNvBlock_InvalidateNvBlock_PS_DCM_ServerNvBlockNeed_EOLUnlockCnt: start-on-event=InvalidateNvBlock, operation=PS_DCM_ServerNvBlockNeed_EOLUnlockCnt.InvalidateNvBlock
        OpEventEraseBlock_EraseBlock_PS_DCM_ServerNvBlockNeed_EOLUnlockCnt: start-on-event=EraseBlock, operation=PS_DCM_ServerNvBlockNeed_EOLUnlockCnt.EraseBlock
        OpEventSetBlockProtection_SetBlockProtection_PAdmin_DCM_ServerNvBlockNeed_EOLUnlockCnt: start-on-event=SetBlockProtection, operation=PAdmin_DCM_ServerNvBlockNeed_EOLUnlockCnt.SetBlockProtection
        OpEventGetErrorStatus_GetErrorStatus_PS_DidDataProcessNvBlockNeed_ClusterInternalConfiguration: start-on-event=GetErrorStatus, operation=PS_DidDataProcessNvBlockNeed_ClusterInternalConfiguration.GetErrorStatus
        OpEventSetRamBlockStatus_SetRamBlockStatus_PS_DidDataProcessNvBlockNeed_ClusterInternalConfiguration: start-on-event=SetRamBlockStatus, operation=PS_DidDataProcessNvBlockNeed_ClusterInternalConfiguration.SetRamBlockStatus
        OpEventReadBlock_ReadBlock_PS_DidDataProcessNvBlockNeed_ClusterInternalConfiguration: start-on-event=ReadBlock, operation=PS_DidDataProcessNvBlockNeed_ClusterInternalConfiguration.ReadBlock
        OpEventWriteBlock_WriteBlock_PS_DidDataProcessNvBlockNeed_ClusterInternalConfiguration: start-on-event=WriteBlock, operation=PS_DidDataProcessNvBlockNeed_ClusterInternalConfiguration.WriteBlock
        OpEventRestoreBlockDefaults_RestoreBlockDefaults_PS_DidDataProcessNvBlockNeed_ClusterInternalConfiguration: start-on-event=RestoreBlockDefaults, operation=PS_DidDataProcessNvBlockNeed_ClusterInternalConfiguration.RestoreBlockDefaults
        OpEventInvalidateNvBlock_InvalidateNvBlock_PS_DidDataProcessNvBlockNeed_ClusterInternalConfiguration: start-on-event=InvalidateNvBlock, operation=PS_DidDataProcessNvBlockNeed_ClusterInternalConfiguration.InvalidateNvBlock
        OpEventEraseBlock_EraseBlock_PS_DidDataProcessNvBlockNeed_ClusterInternalConfiguration: start-on-event=EraseBlock, operation=PS_DidDataProcessNvBlockNeed_ClusterInternalConfiguration.EraseBlock
        OpEventSetBlockProtection_SetBlockProtection_PAdmin_DidDataProcessNvBlockNeed_ClusterInternalConfiguration: start-on-event=SetBlockProtection, operation=PAdmin_DidDataProcessNvBlockNeed_ClusterInternalConfiguration.SetBlockProtection
        OpEventRestoreBlockDefaults_RestoreBlockDefaults_PS_DCM_ServerNvBlockNeedSecAttemptCount: start-on-event=RestoreBlockDefaults, operation=PS_DCM_ServerNvBlockNeedSecAttemptCount.RestoreBlockDefaults
        OpEventRestoreBlockDefaults_RestoreBlockDefaults_PS_DCM_ServerNvBlockNeed_EOLUnlockCnt: start-on-event=RestoreBlockDefaults, operation=PS_DCM_ServerNvBlockNeed_EOLUnlockCnt.RestoreBlockDefaults
        OpEventGetErrorStatus_GetErrorStatus_PS_AMP_NvBlockNeed_LC_Calibration: start-on-event=GetErrorStatus, operation=PS_AMP_NvBlockNeed_LC_Calibration.GetErrorStatus
        OpEventSetRamBlockStatus_SetRamBlockStatus_PS_AMP_NvBlockNeed_LC_Calibration: start-on-event=SetRamBlockStatus, operation=PS_AMP_NvBlockNeed_LC_Calibration.SetRamBlockStatus
        OpEventReadBlock_ReadBlock_PS_AMP_NvBlockNeed_LC_Calibration: start-on-event=ReadBlock, operation=PS_AMP_NvBlockNeed_LC_Calibration.ReadBlock
        OpEventWriteBlock_WriteBlock_PS_AMP_NvBlockNeed_LC_Calibration: start-on-event=WriteBlock, operation=PS_AMP_NvBlockNeed_LC_Calibration.WriteBlock
        OpEventInvalidateNvBlock_InvalidateNvBlock_PS_AMP_NvBlockNeed_LC_Calibration: start-on-event=InvalidateNvBlock, operation=PS_AMP_NvBlockNeed_LC_Calibration.InvalidateNvBlock
        OpEventEraseBlock_EraseBlock_PS_AMP_NvBlockNeed_LC_Calibration: start-on-event=EraseBlock, operation=PS_AMP_NvBlockNeed_LC_Calibration.EraseBlock
        OpEventSetBlockProtection_SetBlockProtection_PAdmin_AMP_NvBlockNeed_LC_Calibration: start-on-event=SetBlockProtection, operation=PAdmin_AMP_NvBlockNeed_LC_Calibration.SetBlockProtection
        OpEventRestoreBlockDefaults_RestoreBlockDefaults_PS_AMP_NvBlockNeed_LC_Calibration: start-on-event=RestoreBlockDefaults, operation=PS_AMP_NvBlockNeed_LC_Calibration.RestoreBlockDefaults
        OpEventGetErrorStatus_GetErrorStatus_PS_DidDataProcessNvBlockNeed_E2ESwitch: start-on-event=GetErrorStatus, operation=PS_DidDataProcessNvBlockNeed_E2ESwitch.GetErrorStatus
        OpEventGetErrorStatus_GetErrorStatus_PS_DidDataProcessNvBlockNeed_SecOcSwitch: start-on-event=GetErrorStatus, operation=PS_DidDataProcessNvBlockNeed_SecOcSwitch.GetErrorStatus
        OpEventSetRamBlockStatus_SetRamBlockStatus_PS_DidDataProcessNvBlockNeed_E2ESwitch: start-on-event=SetRamBlockStatus, operation=PS_DidDataProcessNvBlockNeed_E2ESwitch.SetRamBlockStatus
        OpEventSetRamBlockStatus_SetRamBlockStatus_PS_DidDataProcessNvBlockNeed_SecOcSwitch: start-on-event=SetRamBlockStatus, operation=PS_DidDataProcessNvBlockNeed_SecOcSwitch.SetRamBlockStatus
        OpEventReadBlock_ReadBlock_PS_DidDataProcessNvBlockNeed_E2ESwitch: start-on-event=ReadBlock, operation=PS_DidDataProcessNvBlockNeed_E2ESwitch.ReadBlock
        OpEventReadBlock_ReadBlock_PS_DidDataProcessNvBlockNeed_SecOcSwitch: start-on-event=ReadBlock, operation=PS_DidDataProcessNvBlockNeed_SecOcSwitch.ReadBlock
        OpEventWriteBlock_WriteBlock_PS_DidDataProcessNvBlockNeed_E2ESwitch: start-on-event=WriteBlock, operation=PS_DidDataProcessNvBlockNeed_E2ESwitch.WriteBlock
        OpEventWriteBlock_WriteBlock_PS_DidDataProcessNvBlockNeed_SecOcSwitch: start-on-event=WriteBlock, operation=PS_DidDataProcessNvBlockNeed_SecOcSwitch.WriteBlock
        OpEventRestoreBlockDefaults_RestoreBlockDefaults_PS_DidDataProcessNvBlockNeed_E2ESwitch: start-on-event=RestoreBlockDefaults, operation=PS_DidDataProcessNvBlockNeed_E2ESwitch.RestoreBlockDefaults
        OpEventRestoreBlockDefaults_RestoreBlockDefaults_PS_DidDataProcessNvBlockNeed_SecOcSwitch: start-on-event=RestoreBlockDefaults, operation=PS_DidDataProcessNvBlockNeed_SecOcSwitch.RestoreBlockDefaults
        OpEventInvalidateNvBlock_InvalidateNvBlock_PS_DidDataProcessNvBlockNeed_E2ESwitch: start-on-event=InvalidateNvBlock, operation=PS_DidDataProcessNvBlockNeed_E2ESwitch.InvalidateNvBlock
        OpEventInvalidateNvBlock_InvalidateNvBlock_PS_DidDataProcessNvBlockNeed_SecOcSwitch: start-on-event=InvalidateNvBlock, operation=PS_DidDataProcessNvBlockNeed_SecOcSwitch.InvalidateNvBlock
        OpEventEraseBlock_EraseBlock_PS_DidDataProcessNvBlockNeed_E2ESwitch: start-on-event=EraseBlock, operation=PS_DidDataProcessNvBlockNeed_E2ESwitch.EraseBlock
        OpEventEraseBlock_EraseBlock_PS_DidDataProcessNvBlockNeed_SecOcSwitch: start-on-event=EraseBlock, operation=PS_DidDataProcessNvBlockNeed_SecOcSwitch.EraseBlock
        OpEventSetBlockProtection_SetBlockProtection_PAdmin_DidDataProcessNvBlockNeed_E2ESwitch: start-on-event=SetBlockProtection, operation=PAdmin_DidDataProcessNvBlockNeed_E2ESwitch.SetBlockProtection
        OpEventSetBlockProtection_SetBlockProtection_PAdmin_DidDataProcessNvBlockNeed_SecOcSwitch: start-on-event=SetBlockProtection, operation=PAdmin_DidDataProcessNvBlockNeed_SecOcSwitch.SetBlockProtection
        OpEventGetErrorStatus_GetErrorStatus_PS_NvBlockNeed_UpgradeResetFlag: start-on-event=GetErrorStatus, operation=PS_NvBlockNeed_UpgradeResetFlag.GetErrorStatus
        OpEventSetRamBlockStatus_SetRamBlockStatus_PS_NvBlockNeed_UpgradeResetFlag: start-on-event=SetRamBlockStatus, operation=PS_NvBlockNeed_UpgradeResetFlag.SetRamBlockStatus
        OpEventReadBlock_ReadBlock_PS_NvBlockNeed_UpgradeResetFlag: start-on-event=ReadBlock, operation=PS_NvBlockNeed_UpgradeResetFlag.ReadBlock
        OpEventWriteBlock_WriteBlock_PS_NvBlockNeed_UpgradeResetFlag: start-on-event=WriteBlock, operation=PS_NvBlockNeed_UpgradeResetFlag.WriteBlock
        OpEventInvalidateNvBlock_InvalidateNvBlock_PS_NvBlockNeed_UpgradeResetFlag: start-on-event=InvalidateNvBlock, operation=PS_NvBlockNeed_UpgradeResetFlag.InvalidateNvBlock
        OpEventEraseBlock_EraseBlock_PS_NvBlockNeed_UpgradeResetFlag: start-on-event=EraseBlock, operation=PS_NvBlockNeed_UpgradeResetFlag.EraseBlock
        OpEventSetBlockProtection_SetBlockProtection_PAdmin_NvBlockNeed_UpgradeResetFlag: start-on-event=SetBlockProtection, operation=PAdmin_NvBlockNeed_UpgradeResetFlag.SetBlockProtection
        OpEventRestoreBlockDefaults_RestoreBlockDefaults_PS_NvBlockNeed_UpgradeResetFlag: start-on-event=RestoreBlockDefaults, operation=PS_NvBlockNeed_UpgradeResetFlag.RestoreBlockDefaults
        OpEventGetErrorStatus_GetErrorStatus_PS_NvMBlockDescriptor_Fvm_TripCount: start-on-event=GetErrorStatus, operation=PS_NvMBlockDescriptor_Fvm_TripCount.GetErrorStatus
        OpEventSetRamBlockStatus_SetRamBlockStatus_PS_NvMBlockDescriptor_Fvm_TripCount: start-on-event=SetRamBlockStatus, operation=PS_NvMBlockDescriptor_Fvm_TripCount.SetRamBlockStatus
        OpEventReadBlock_ReadBlock_PS_NvMBlockDescriptor_Fvm_TripCount: start-on-event=ReadBlock, operation=PS_NvMBlockDescriptor_Fvm_TripCount.ReadBlock
        OpEventWriteBlock_WriteBlock_PS_NvMBlockDescriptor_Fvm_TripCount: start-on-event=WriteBlock, operation=PS_NvMBlockDescriptor_Fvm_TripCount.WriteBlock
        OpEventRestoreBlockDefaults_RestoreBlockDefaults_PS_NvMBlockDescriptor_Fvm_TripCount: start-on-event=RestoreBlockDefaults, operation=PS_NvMBlockDescriptor_Fvm_TripCount.RestoreBlockDefaults
        OpEventInvalidateNvBlock_InvalidateNvBlock_PS_NvMBlockDescriptor_Fvm_TripCount: start-on-event=InvalidateNvBlock, operation=PS_NvMBlockDescriptor_Fvm_TripCount.InvalidateNvBlock
        OpEventEraseBlock_EraseBlock_PS_NvMBlockDescriptor_Fvm_TripCount: start-on-event=EraseBlock, operation=PS_NvMBlockDescriptor_Fvm_TripCount.EraseBlock
        OpEventSetBlockProtection_SetBlockProtection_PAdmin_NvMBlockDescriptor_Fvm_TripCount: start-on-event=SetBlockProtection, operation=PAdmin_NvMBlockDescriptor_Fvm_TripCount.SetBlockProtection
        OpEventGetErrorStatus_GetErrorStatus_PS_Common_NormalNvBlockNeed_Menu: start-on-event=GetErrorStatus, operation=PS_Common_NormalNvBlockNeed_Menu.GetErrorStatus
        OpEventSetRamBlockStatus_SetRamBlockStatus_PS_Common_NormalNvBlockNeed_Menu: start-on-event=SetRamBlockStatus, operation=PS_Common_NormalNvBlockNeed_Menu.SetRamBlockStatus
        OpEventReadBlock_ReadBlock_PS_Common_NormalNvBlockNeed_Menu: start-on-event=ReadBlock, operation=PS_Common_NormalNvBlockNeed_Menu.ReadBlock
        OpEventWriteBlock_WriteBlock_PS_Common_NormalNvBlockNeed_Menu: start-on-event=WriteBlock, operation=PS_Common_NormalNvBlockNeed_Menu.WriteBlock
        OpEventInvalidateNvBlock_InvalidateNvBlock_PS_Common_NormalNvBlockNeed_Menu: start-on-event=InvalidateNvBlock, operation=PS_Common_NormalNvBlockNeed_Menu.InvalidateNvBlock
        OpEventEraseBlock_EraseBlock_PS_Common_NormalNvBlockNeed_Menu: start-on-event=EraseBlock, operation=PS_Common_NormalNvBlockNeed_Menu.EraseBlock
        OpEventSetBlockProtection_SetBlockProtection_PAdmin_Common_NormalNvBlockNeed_Menu: start-on-event=SetBlockProtection, operation=PAdmin_Common_NormalNvBlockNeed_Menu.SetBlockProtection
        OpEventRestoreBlockDefaults_RestoreBlockDefaults_PS_Common_NormalNvBlockNeed_Menu: start-on-event=RestoreBlockDefaults, operation=PS_Common_NormalNvBlockNeed_Menu.RestoreBlockDefaults
        OpEventGetErrorStatus_GetErrorStatus_PS_DidDataProcessNvBlockNeed_VehicleSoftwareVersion: start-on-event=GetErrorStatus, operation=PS_DidDataProcessNvBlockNeed_VehicleSoftwareVersion.GetErrorStatus
        OpEventSetRamBlockStatus_SetRamBlockStatus_PS_DidDataProcessNvBlockNeed_VehicleSoftwareVersion: start-on-event=SetRamBlockStatus, operation=PS_DidDataProcessNvBlockNeed_VehicleSoftwareVersion.SetRamBlockStatus
        OpEventReadBlock_ReadBlock_PS_DidDataProcessNvBlockNeed_VehicleSoftwareVersion: start-on-event=ReadBlock, operation=PS_DidDataProcessNvBlockNeed_VehicleSoftwareVersion.ReadBlock
        OpEventWriteBlock_WriteBlock_PS_DidDataProcessNvBlockNeed_VehicleSoftwareVersion: start-on-event=WriteBlock, operation=PS_DidDataProcessNvBlockNeed_VehicleSoftwareVersion.WriteBlock
        OpEventRestoreBlockDefaults_RestoreBlockDefaults_PS_DidDataProcessNvBlockNeed_VehicleSoftwareVersion: start-on-event=RestoreBlockDefaults, operation=PS_DidDataProcessNvBlockNeed_VehicleSoftwareVersion.RestoreBlockDefaults
        OpEventInvalidateNvBlock_InvalidateNvBlock_PS_DidDataProcessNvBlockNeed_VehicleSoftwareVersion: start-on-event=InvalidateNvBlock, operation=PS_DidDataProcessNvBlockNeed_VehicleSoftwareVersion.InvalidateNvBlock
        OpEventEraseBlock_EraseBlock_PS_DidDataProcessNvBlockNeed_VehicleSoftwareVersion: start-on-event=EraseBlock, operation=PS_DidDataProcessNvBlockNeed_VehicleSoftwareVersion.EraseBlock
        OpEventSetBlockProtection_SetBlockProtection_PAdmin_DidDataProcessNvBlockNeed_VehicleSoftwareVersion: start-on-event=SetBlockProtection, operation=PAdmin_DidDataProcessNvBlockNeed_VehicleSoftwareVersion.SetBlockProtection
        OpEventGetErrorStatus_GetErrorStatus_PS_AMP_NvBlockNeed_LC_Calibration2: start-on-event=GetErrorStatus, operation=PS_AMP_NvBlockNeed_LC_Calibration2.GetErrorStatus
        OpEventSetRamBlockStatus_SetRamBlockStatus_PS_AMP_NvBlockNeed_LC_Calibration2: start-on-event=SetRamBlockStatus, operation=PS_AMP_NvBlockNeed_LC_Calibration2.SetRamBlockStatus
        OpEventReadBlock_ReadBlock_PS_AMP_NvBlockNeed_LC_Calibration2: start-on-event=ReadBlock, operation=PS_AMP_NvBlockNeed_LC_Calibration2.ReadBlock
        OpEventWriteBlock_WriteBlock_PS_AMP_NvBlockNeed_LC_Calibration2: start-on-event=WriteBlock, operation=PS_AMP_NvBlockNeed_LC_Calibration2.WriteBlock
        OpEventRestoreBlockDefaults_RestoreBlockDefaults_PS_AMP_NvBlockNeed_LC_Calibration2: start-on-event=RestoreBlockDefaults, operation=PS_AMP_NvBlockNeed_LC_Calibration2.RestoreBlockDefaults
        OpEventInvalidateNvBlock_InvalidateNvBlock_PS_AMP_NvBlockNeed_LC_Calibration2: start-on-event=InvalidateNvBlock, operation=PS_AMP_NvBlockNeed_LC_Calibration2.InvalidateNvBlock
        OpEventEraseBlock_EraseBlock_PS_AMP_NvBlockNeed_LC_Calibration2: start-on-event=EraseBlock, operation=PS_AMP_NvBlockNeed_LC_Calibration2.EraseBlock
        OpEventSetBlockProtection_SetBlockProtection_PAdmin_AMP_NvBlockNeed_LC_Calibration2: start-on-event=SetBlockProtection, operation=PAdmin_AMP_NvBlockNeed_LC_Calibration2.SetBlockProtection
        OpEventGetErrorStatus_GetErrorStatus_PS_SOCManagerNvBlockNeed_HealthSwitch: start-on-event=GetErrorStatus, operation=PS_SOCManagerNvBlockNeed_HealthSwitch.GetErrorStatus
        OpEventSetRamBlockStatus_SetRamBlockStatus_PS_SOCManagerNvBlockNeed_HealthSwitch: start-on-event=SetRamBlockStatus, operation=PS_SOCManagerNvBlockNeed_HealthSwitch.SetRamBlockStatus
        OpEventReadBlock_ReadBlock_PS_SOCManagerNvBlockNeed_HealthSwitch: start-on-event=ReadBlock, operation=PS_SOCManagerNvBlockNeed_HealthSwitch.ReadBlock
        OpEventWriteBlock_WriteBlock_PS_SOCManagerNvBlockNeed_HealthSwitch: start-on-event=WriteBlock, operation=PS_SOCManagerNvBlockNeed_HealthSwitch.WriteBlock
        OpEventInvalidateNvBlock_InvalidateNvBlock_PS_SOCManagerNvBlockNeed_HealthSwitch: start-on-event=InvalidateNvBlock, operation=PS_SOCManagerNvBlockNeed_HealthSwitch.InvalidateNvBlock
        OpEventEraseBlock_EraseBlock_PS_SOCManagerNvBlockNeed_HealthSwitch: start-on-event=EraseBlock, operation=PS_SOCManagerNvBlockNeed_HealthSwitch.EraseBlock
        OpEventSetBlockProtection_SetBlockProtection_PAdmin_SOCManagerNvBlockNeed_HealthSwitch: start-on-event=SetBlockProtection, operation=PAdmin_SOCManagerNvBlockNeed_HealthSwitch.SetBlockProtection
        OpEventRestoreBlockDefaults_RestoreBlockDefaults_PS_SOCManagerNvBlockNeed_HealthSwitch: start-on-event=RestoreBlockDefaults, operation=PS_SOCManagerNvBlockNeed_HealthSwitch.RestoreBlockDefaults
        OpEventGetErrorStatus_GetErrorStatus_PS_DidDataProcessNvBlockNeed_ClusterDisplayHMIAdjustmentOffset: start-on-event=GetErrorStatus, operation=PS_DidDataProcessNvBlockNeed_ClusterDisplayHMIAdjustmentOffset.GetErrorStatus
        OpEventSetRamBlockStatus_SetRamBlockStatus_PS_DidDataProcessNvBlockNeed_ClusterDisplayHMIAdjustmentOffset: start-on-event=SetRamBlockStatus, operation=PS_DidDataProcessNvBlockNeed_ClusterDisplayHMIAdjustmentOffset.SetRamBlockStatus
        OpEventReadBlock_ReadBlock_PS_DidDataProcessNvBlockNeed_ClusterDisplayHMIAdjustmentOffset: start-on-event=ReadBlock, operation=PS_DidDataProcessNvBlockNeed_ClusterDisplayHMIAdjustmentOffset.ReadBlock
        OpEventWriteBlock_WriteBlock_PS_DidDataProcessNvBlockNeed_ClusterDisplayHMIAdjustmentOffset: start-on-event=WriteBlock, operation=PS_DidDataProcessNvBlockNeed_ClusterDisplayHMIAdjustmentOffset.WriteBlock
        OpEventRestoreBlockDefaults_RestoreBlockDefaults_PS_DidDataProcessNvBlockNeed_ClusterDisplayHMIAdjustmentOffset: start-on-event=RestoreBlockDefaults, operation=PS_DidDataProcessNvBlockNeed_ClusterDisplayHMIAdjustmentOffset.RestoreBlockDefaults
        OpEventInvalidateNvBlock_InvalidateNvBlock_PS_DidDataProcessNvBlockNeed_ClusterDisplayHMIAdjustmentOffset: start-on-event=InvalidateNvBlock, operation=PS_DidDataProcessNvBlockNeed_ClusterDisplayHMIAdjustmentOffset.InvalidateNvBlock
        OpEventEraseBlock_EraseBlock_PS_DidDataProcessNvBlockNeed_ClusterDisplayHMIAdjustmentOffset: start-on-event=EraseBlock, operation=PS_DidDataProcessNvBlockNeed_ClusterDisplayHMIAdjustmentOffset.EraseBlock
        OpEventSetBlockProtection_SetBlockProtection_PAdmin_DidDataProcessNvBlockNeed_ClusterDisplayHMIAdjustmentOffset: start-on-event=SetBlockProtection, operation=PAdmin_DidDataProcessNvBlockNeed_ClusterDisplayHMIAdjustmentOffset.SetBlockProtection
        OpEventGetErrorStatus_GetErrorStatus_PS_Can_ServerNvBlockNeed_AbnormalWakeupSleepRecords: start-on-event=GetErrorStatus, operation=PS_Can_ServerNvBlockNeed_AbnormalWakeupSleepRecords.GetErrorStatus
        OpEventGetErrorStatus_GetErrorStatus_PS_Can_ServerNvBlockNeed_ActiveWUCounter: start-on-event=GetErrorStatus, operation=PS_Can_ServerNvBlockNeed_ActiveWUCounter.GetErrorStatus
        OpEventSetRamBlockStatus_SetRamBlockStatus_PS_Can_ServerNvBlockNeed_AbnormalWakeupSleepRecords: start-on-event=SetRamBlockStatus, operation=PS_Can_ServerNvBlockNeed_AbnormalWakeupSleepRecords.SetRamBlockStatus
        OpEventSetRamBlockStatus_SetRamBlockStatus_PS_Can_ServerNvBlockNeed_ActiveWUCounter: start-on-event=SetRamBlockStatus, operation=PS_Can_ServerNvBlockNeed_ActiveWUCounter.SetRamBlockStatus
        OpEventReadBlock_ReadBlock_PS_Can_ServerNvBlockNeed_AbnormalWakeupSleepRecords: start-on-event=ReadBlock, operation=PS_Can_ServerNvBlockNeed_AbnormalWakeupSleepRecords.ReadBlock
        OpEventReadBlock_ReadBlock_PS_Can_ServerNvBlockNeed_ActiveWUCounter: start-on-event=ReadBlock, operation=PS_Can_ServerNvBlockNeed_ActiveWUCounter.ReadBlock
        OpEventWriteBlock_WriteBlock_PS_Can_ServerNvBlockNeed_AbnormalWakeupSleepRecords: start-on-event=WriteBlock, operation=PS_Can_ServerNvBlockNeed_AbnormalWakeupSleepRecords.WriteBlock
        OpEventWriteBlock_WriteBlock_PS_Can_ServerNvBlockNeed_ActiveWUCounter: start-on-event=WriteBlock, operation=PS_Can_ServerNvBlockNeed_ActiveWUCounter.WriteBlock
        OpEventRestoreBlockDefaults_RestoreBlockDefaults_PS_Can_ServerNvBlockNeed_AbnormalWakeupSleepRecords: start-on-event=RestoreBlockDefaults, operation=PS_Can_ServerNvBlockNeed_AbnormalWakeupSleepRecords.RestoreBlockDefaults
        OpEventRestoreBlockDefaults_RestoreBlockDefaults_PS_Can_ServerNvBlockNeed_ActiveWUCounter: start-on-event=RestoreBlockDefaults, operation=PS_Can_ServerNvBlockNeed_ActiveWUCounter.RestoreBlockDefaults
        OpEventInvalidateNvBlock_InvalidateNvBlock_PS_Can_ServerNvBlockNeed_AbnormalWakeupSleepRecords: start-on-event=InvalidateNvBlock, operation=PS_Can_ServerNvBlockNeed_AbnormalWakeupSleepRecords.InvalidateNvBlock
        OpEventInvalidateNvBlock_InvalidateNvBlock_PS_Can_ServerNvBlockNeed_ActiveWUCounter: start-on-event=InvalidateNvBlock, operation=PS_Can_ServerNvBlockNeed_ActiveWUCounter.InvalidateNvBlock
        OpEventEraseBlock_EraseBlock_PS_Can_ServerNvBlockNeed_AbnormalWakeupSleepRecords: start-on-event=EraseBlock, operation=PS_Can_ServerNvBlockNeed_AbnormalWakeupSleepRecords.EraseBlock
        OpEventEraseBlock_EraseBlock_PS_Can_ServerNvBlockNeed_ActiveWUCounter: start-on-event=EraseBlock, operation=PS_Can_ServerNvBlockNeed_ActiveWUCounter.EraseBlock
        OpEventSetBlockProtection_SetBlockProtection_PAdmin_Can_ServerNvBlockNeed_AbnormalWakeupSleepRecords: start-on-event=SetBlockProtection, operation=PAdmin_Can_ServerNvBlockNeed_AbnormalWakeupSleepRecords.SetBlockProtection
        OpEventSetBlockProtection_SetBlockProtection_PAdmin_Can_ServerNvBlockNeed_ActiveWUCounter: start-on-event=SetBlockProtection, operation=PAdmin_Can_ServerNvBlockNeed_ActiveWUCounter.SetBlockProtection
      port-api-options:
        enable-take-address=true, indirect-api=false, port=NvM_RpNotifyJobEnd_Common_NormalNvBlockNeed_Block_ODO_{1..5}
        enable-take-address=true, indirect-api=false, port=NvM_RpNotifyJobEnd_Common_NormalNvBlockNeed_Block_MaintainOdo
        enable-take-address=true, indirect-api=false, port=NvM_RpNotifyJobEnd_Common_NormalNvBlockNeed_Block_Trip
        enable-take-address=true, indirect-api=false, port=NvM_RpNotifyJobEnd_DidDataProcessNvBlockNeed_FactoryMode
        enable-take-address=true, indirect-api=false, port=NvM_RpNotifyJobEnd_DidDataProcessNvBlockNeed_VIN
        enable-take-address=true, indirect-api=false, port=NvM_RpNotifyJobEnd_DidDataProcessNvBlockNeed_VehicleMode
        enable-take-address=true, indirect-api=false, port=NvM_RpNotifyJobEnd_DidDataProcessNvBlockNeed_ECUlevelNetworkConfigurationData
        enable-take-address=true, indirect-api=false, port=NvM_RpNotifyJobEnd_EOL_NvBlockNeed_0xF18C
        enable-take-address=true, indirect-api=false, port=NvM_RpNotifyJobEnd_EOL_NvBlockNeed_0xF193
        enable-take-address=true, indirect-api=false, port=NvM_RpNotifyJobEnd_EOL_NvBlockNeed_0xF195
        enable-take-address=true, indirect-api=false, port=NvM_RpNotifyJobEnd_EOL_NvBlockNeed_0xFD00
        enable-take-address=true, indirect-api=false, port=NvM_RpNotifyJobEnd_EOL_NvBlockNeed_0xFD19
        enable-take-address=true, indirect-api=false, port=NvM_RpNotifyJobEnd_EOL_NvBlockNeed_0xFE{20..25}
        enable-take-address=true, indirect-api=false, port=NvM_RpNotifyJobEnd_EOL_NvBlockNeed_0xF187
        enable-take-address=true, indirect-api=false, port=NvM_RpNotifyJobEnd_Common_GateWayNvBlockNeed_Block_IPC_Config_Data
        enable-take-address=true, indirect-api=false, port=NvM_RpNotifyJobEnd_Common_GateWayNvBlockNeed_Block_IPC_CAN_Data
        enable-take-address=true, indirect-api=false, port=NvM_RpNotifyJobEnd_DidDataProcessNvBlockNeed_ClusterInternalConfiguration
        {enable-take-address=true, indirect-api=false, port-defined-argument-value{value=13, value-type=NvM_BlockIdType}, port=PS_Common_NormalNvBlockNeed_Block_ODO_1}
        {enable-take-address=true, indirect-api=false, port-defined-argument-value{value=13, value-type=NvM_BlockIdType}, port=PAdmin_Common_NormalNvBlockNeed_Block_ODO_1}
        {enable-take-address=true, indirect-api=false, port-defined-argument-value{value=15, value-type=NvM_BlockIdType}, port=PS_Common_NormalNvBlockNeed_Block_ODO_2}
        {enable-take-address=true, indirect-api=false, port-defined-argument-value{value=15, value-type=NvM_BlockIdType}, port=PAdmin_Common_NormalNvBlockNeed_Block_ODO_2}
        {enable-take-address=true, indirect-api=false, port-defined-argument-value{value=17, value-type=NvM_BlockIdType}, port=PS_Common_NormalNvBlockNeed_Block_ODO_3}
        {enable-take-address=true, indirect-api=false, port-defined-argument-value{value=17, value-type=NvM_BlockIdType}, port=PAdmin_Common_NormalNvBlockNeed_Block_ODO_3}
        {enable-take-address=true, indirect-api=false, port-defined-argument-value{value=19, value-type=NvM_BlockIdType}, port=PS_Common_NormalNvBlockNeed_Block_ODO_4}
        {enable-take-address=true, indirect-api=false, port-defined-argument-value{value=19, value-type=NvM_BlockIdType}, port=PAdmin_Common_NormalNvBlockNeed_Block_ODO_4}
        {enable-take-address=true, indirect-api=false, port-defined-argument-value{value=21, value-type=NvM_BlockIdType}, port=PS_Common_NormalNvBlockNeed_Block_ODO_5}
        {enable-take-address=true, indirect-api=false, port-defined-argument-value{value=21, value-type=NvM_BlockIdType}, port=PAdmin_Common_NormalNvBlockNeed_Block_ODO_5}
        {enable-take-address=true, indirect-api=false, port-defined-argument-value{value=23, value-type=NvM_BlockIdType}, port=PS_Common_NormalNvBlockNeed_Block_MaintainOdo}
        {enable-take-address=true, indirect-api=false, port-defined-argument-value{value=23, value-type=NvM_BlockIdType}, port=PAdmin_Common_NormalNvBlockNeed_Block_MaintainOdo}
        {enable-take-address=true, indirect-api=false, port-defined-argument-value{value=25, value-type=NvM_BlockIdType}, port=PS_Common_NormalNvBlockNeed_Block_Trip}
        {enable-take-address=true, indirect-api=false, port-defined-argument-value{value=25, value-type=NvM_BlockIdType}, port=PAdmin_Common_NormalNvBlockNeed_Block_Trip}
        {enable-take-address=true, indirect-api=false, port-defined-argument-value{value=29, value-type=NvM_BlockIdType}, port=PS_DidDataProcessNvBlockNeed_FactoryMode}
        {enable-take-address=true, indirect-api=false, port-defined-argument-value{value=29, value-type=NvM_BlockIdType}, port=PAdmin_DidDataProcessNvBlockNeed_FactoryMode}
        {enable-take-address=true, indirect-api=false, port-defined-argument-value{value=33, value-type=NvM_BlockIdType}, port=PS_DidDataProcessNvBlockNeed_VIN}
        {enable-take-address=true, indirect-api=false, port-defined-argument-value{value=33, value-type=NvM_BlockIdType}, port=PAdmin_DidDataProcessNvBlockNeed_VIN}
        {enable-take-address=true, indirect-api=false, port-defined-argument-value{value=34, value-type=NvM_BlockIdType}, port=PS_DidDataProcessNvBlockNeed_VehicleMode}
        {enable-take-address=true, indirect-api=false, port-defined-argument-value{value=34, value-type=NvM_BlockIdType}, port=PAdmin_DidDataProcessNvBlockNeed_VehicleMode}
        {enable-take-address=true, indirect-api=false, port-defined-argument-value{value=31, value-type=NvM_BlockIdType}, port=PS_DidDataProcessNvBlockNeed_ECUlevelNetworkConfigurationData}
        {enable-take-address=true, indirect-api=false, port-defined-argument-value{value=31, value-type=NvM_BlockIdType}, port=PAdmin_DidDataProcessNvBlockNeed_ECUlevelNetworkConfigurationData}
        {enable-take-address=true, indirect-api=false, port-defined-argument-value{value=35, value-type=NvM_BlockIdType}, port=PS_EOL_NvBlockNeed_0xF18C}
        {enable-take-address=true, indirect-api=false, port-defined-argument-value{value=35, value-type=NvM_BlockIdType}, port=PAdmin_EOL_NvBlockNeed_0xF18C}
        {enable-take-address=true, indirect-api=false, port-defined-argument-value{value=36, value-type=NvM_BlockIdType}, port=PS_EOL_NvBlockNeed_0xF193}
        {enable-take-address=true, indirect-api=false, port-defined-argument-value{value=36, value-type=NvM_BlockIdType}, port=PAdmin_EOL_NvBlockNeed_0xF193}
        {enable-take-address=true, indirect-api=false, port-defined-argument-value{value=37, value-type=NvM_BlockIdType}, port=PS_EOL_NvBlockNeed_0xF195}
        {enable-take-address=true, indirect-api=false, port-defined-argument-value{value=37, value-type=NvM_BlockIdType}, port=PAdmin_EOL_NvBlockNeed_0xF195}
        {enable-take-address=true, indirect-api=false, port-defined-argument-value{value=38, value-type=NvM_BlockIdType}, port=PS_EOL_NvBlockNeed_0xFD00}
        {enable-take-address=true, indirect-api=false, port-defined-argument-value{value=38, value-type=NvM_BlockIdType}, port=PAdmin_EOL_NvBlockNeed_0xFD00}
        {enable-take-address=true, indirect-api=false, port-defined-argument-value{value=39, value-type=NvM_BlockIdType}, port=PS_EOL_NvBlockNeed_0xFD19}
        {enable-take-address=true, indirect-api=false, port-defined-argument-value{value=39, value-type=NvM_BlockIdType}, port=PAdmin_EOL_NvBlockNeed_0xFD19}
        enable-take-address=true, indirect-api=false, port=NvM_RpNotifyJobEnd_AMP_NvBlockNeed_LC_Calibration
        enable-take-address=true, indirect-api=false, port=NvM_RpNotifyJobEnd_DidDataProcessNvBlockNeed_E2ESwitch
        enable-take-address=true, indirect-api=false, port=NvM_RpNotifyJobEnd_DidDataProcessNvBlockNeed_SecOcSwitch
        enable-take-address=true, indirect-api=false, port=NvM_RpNotifyJobEnd_NvMBlockDescriptor_Fvm_TripCount
        enable-take-address=true, indirect-api=false, port=NvM_RpNotifyJobEnd_Common_NormalNvBlockNeed_Menu
        {enable-take-address=true, indirect-api=false, port-defined-argument-value{value=40, value-type=NvM_BlockIdType}, port=PS_EOL_NvBlockNeed_0xFE20}
        {enable-take-address=true, indirect-api=false, port-defined-argument-value{value=40, value-type=NvM_BlockIdType}, port=PAdmin_EOL_NvBlockNeed_0xFE20}
        {enable-take-address=true, indirect-api=false, port-defined-argument-value{value=41, value-type=NvM_BlockIdType}, port=PS_EOL_NvBlockNeed_0xFE21}
        {enable-take-address=true, indirect-api=false, port-defined-argument-value{value=41, value-type=NvM_BlockIdType}, port=PAdmin_EOL_NvBlockNeed_0xFE21}
        {enable-take-address=true, indirect-api=false, port-defined-argument-value{value=42, value-type=NvM_BlockIdType}, port=PS_EOL_NvBlockNeed_0xFE22}
        {enable-take-address=true, indirect-api=false, port-defined-argument-value{value=42, value-type=NvM_BlockIdType}, port=PAdmin_EOL_NvBlockNeed_0xFE22}
        {enable-take-address=true, indirect-api=false, port-defined-argument-value{value=43, value-type=NvM_BlockIdType}, port=PS_EOL_NvBlockNeed_0xFE23}
        {enable-take-address=true, indirect-api=false, port-defined-argument-value{value=43, value-type=NvM_BlockIdType}, port=PAdmin_EOL_NvBlockNeed_0xFE23}
        {enable-take-address=true, indirect-api=false, port-defined-argument-value{value=44, value-type=NvM_BlockIdType}, port=PS_EOL_NvBlockNeed_0xFE24}
        {enable-take-address=true, indirect-api=false, port-defined-argument-value{value=44, value-type=NvM_BlockIdType}, port=PAdmin_EOL_NvBlockNeed_0xFE24}
        {enable-take-address=true, indirect-api=false, port-defined-argument-value{value=45, value-type=NvM_BlockIdType}, port=PS_EOL_NvBlockNeed_0xFE25}
        {enable-take-address=true, indirect-api=false, port-defined-argument-value{value=45, value-type=NvM_BlockIdType}, port=PAdmin_EOL_NvBlockNeed_0xFE25}
        {enable-take-address=true, indirect-api=false, port-defined-argument-value{value=46, value-type=NvM_BlockIdType}, port=PS_EOL_NvBlockNeed_0xF187}
        {enable-take-address=true, indirect-api=false, port-defined-argument-value{value=46, value-type=NvM_BlockIdType}, port=PAdmin_EOL_NvBlockNeed_0xF187}
        {enable-take-address=true, indirect-api=false, port-defined-argument-value{value=47, value-type=NvM_BlockIdType}, port=PS_Common_GateWayNvBlockNeed_Block_IPC_Config_Data}
        {enable-take-address=true, indirect-api=false, port-defined-argument-value{value=47, value-type=NvM_BlockIdType}, port=PAdmin_Common_GateWayNvBlockNeed_Block_IPC_Config_Data}
        {enable-take-address=true, indirect-api=false, port-defined-argument-value{value=48, value-type=NvM_BlockIdType}, port=PS_Common_GateWayNvBlockNeed_Block_IPC_CAN_Data}
        {enable-take-address=true, indirect-api=false, port-defined-argument-value{value=48, value-type=NvM_BlockIdType}, port=PAdmin_Common_GateWayNvBlockNeed_Block_IPC_CAN_Data}
        {enable-take-address=true, indirect-api=false, port-defined-argument-value{value=49, value-type=NvM_BlockIdType}, port=PS_MiscNvBlockNeed_ResetInfomation}
        {enable-take-address=true, indirect-api=false, port-defined-argument-value{value=49, value-type=NvM_BlockIdType}, port=PAdmin_MiscNvBlockNeed_ResetInfomation}
        {enable-take-address=true, indirect-api=false, port-defined-argument-value{value=50, value-type=NvM_BlockIdType}, port=PS_DCM_ServerNvBlockNeedSecAttemptCount}
        {enable-take-address=true, indirect-api=false, port-defined-argument-value{value=50, value-type=NvM_BlockIdType}, port=PAdmin_DCM_ServerNvBlockNeedSecAttemptCount}
        {enable-take-address=true, indirect-api=false, port-defined-argument-value{value=51, value-type=NvM_BlockIdType}, port=PS_DCM_ServerNvBlockNeed_EOLUnlockCnt}
        {enable-take-address=true, indirect-api=false, port-defined-argument-value{value=51, value-type=NvM_BlockIdType}, port=PAdmin_DCM_ServerNvBlockNeed_EOLUnlockCnt}
        {enable-take-address=true, indirect-api=false, port-defined-argument-value{value=52, value-type=NvM_BlockIdType}, port=PS_DidDataProcessNvBlockNeed_ClusterInternalConfiguration}
        {enable-take-address=true, indirect-api=false, port-defined-argument-value{value=52, value-type=NvM_BlockIdType}, port=PAdmin_DidDataProcessNvBlockNeed_ClusterInternalConfiguration}
        {enable-take-address=true, indirect-api=false, port-defined-argument-value{value=53, value-type=NvM_BlockIdType}, port=PS_AMP_NvBlockNeed_LC_Calibration}
        {enable-take-address=true, indirect-api=false, port-defined-argument-value{value=53, value-type=NvM_BlockIdType}, port=PAdmin_AMP_NvBlockNeed_LC_Calibration}
        {enable-take-address=true, indirect-api=false, port-defined-argument-value{value=54, value-type=NvM_BlockIdType}, port=PS_DidDataProcessNvBlockNeed_E2ESwitch}
        {enable-take-address=true, indirect-api=false, port-defined-argument-value{value=54, value-type=NvM_BlockIdType}, port=PAdmin_DidDataProcessNvBlockNeed_E2ESwitch}
        {enable-take-address=true, indirect-api=false, port-defined-argument-value{value=55, value-type=NvM_BlockIdType}, port=PS_DidDataProcessNvBlockNeed_SecOcSwitch}
        {enable-take-address=true, indirect-api=false, port-defined-argument-value{value=55, value-type=NvM_BlockIdType}, port=PAdmin_DidDataProcessNvBlockNeed_SecOcSwitch}
        {enable-take-address=true, indirect-api=false, port-defined-argument-value{value=56, value-type=NvM_BlockIdType}, port=PS_NvBlockNeed_UpgradeResetFlag}
        {enable-take-address=true, indirect-api=false, port-defined-argument-value{value=56, value-type=NvM_BlockIdType}, port=PAdmin_NvBlockNeed_UpgradeResetFlag}
        {enable-take-address=true, indirect-api=false, port-defined-argument-value{value=57, value-type=NvM_BlockIdType}, port=PS_NvMBlockDescriptor_Fvm_TripCount}
        {enable-take-address=true, indirect-api=false, port-defined-argument-value{value=57, value-type=NvM_BlockIdType}, port=PAdmin_NvMBlockDescriptor_Fvm_TripCount}
        {enable-take-address=true, indirect-api=false, port-defined-argument-value{value=58, value-type=NvM_BlockIdType}, port=PS_Common_NormalNvBlockNeed_Menu}
        {enable-take-address=true, indirect-api=false, port-defined-argument-value{value=58, value-type=NvM_BlockIdType}, port=PAdmin_Common_NormalNvBlockNeed_Menu}
        {enable-take-address=true, indirect-api=false, port-defined-argument-value{value=59, value-type=NvM_BlockIdType}, port=PS_DidDataProcessNvBlockNeed_VehicleSoftwareVersion}
        {enable-take-address=true, indirect-api=false, port-defined-argument-value{value=59, value-type=NvM_BlockIdType}, port=PAdmin_DidDataProcessNvBlockNeed_VehicleSoftwareVersion}
        enable-take-address=true, indirect-api=false, port=NvM_RpNotifyJobEnd_DidDataProcessNvBlockNeed_VehicleSoftwareVersion
        {enable-take-address=true, indirect-api=false, port-defined-argument-value{value=60, value-type=NvM_BlockIdType}, port=PS_AMP_NvBlockNeed_LC_Calibration2}
        {enable-take-address=true, indirect-api=false, port-defined-argument-value{value=60, value-type=NvM_BlockIdType}, port=PAdmin_AMP_NvBlockNeed_LC_Calibration2}
        enable-take-address=true, indirect-api=false, port=NvM_RpNotifyJobEnd_AMP_NvBlockNeed_LC_Calibration2
        {enable-take-address=true, indirect-api=false, port-defined-argument-value{value=61, value-type=NvM_BlockIdType}, port=PAdmin_SOCManagerNvBlockNeed_HealthSwitch}
        enable-take-address=true, indirect-api=false, port=NvM_RpNotifyJobEnd_SOCManagerNvBlockNeed_HealthSwitch
        {enable-take-address=true, indirect-api=false, port-defined-argument-value{value=61, value-type=NvM_BlockIdType}, port=PS_SOCManagerNvBlockNeed_HealthSwitch}
        {enable-take-address=true, indirect-api=false, port-defined-argument-value{value=62, value-type=NvM_BlockIdType}, port=PS_DidDataProcessNvBlockNeed_ClusterDisplayHMIAdjustmentOffset}
        {enable-take-address=true, indirect-api=false, port-defined-argument-value{value=62, value-type=NvM_BlockIdType}, port=PAdmin_DidDataProcessNvBlockNeed_ClusterDisplayHMIAdjustmentOffset}
        enable-take-address=true, indirect-api=false, port=NvM_RpNotifyJobEnd_DidDataProcessNvBlockNeed_ClusterDisplayHMIAdjustmentOffset
        {enable-take-address=true, indirect-api=false, port-defined-argument-value{value=63, value-type=NvM_BlockIdType}, port=PS_Can_ServerNvBlockNeed_AbnormalWakeupSleepRecords}
        {enable-take-address=true, indirect-api=false, port-defined-argument-value{value=63, value-type=NvM_BlockIdType}, port=PAdmin_Can_ServerNvBlockNeed_AbnormalWakeupSleepRecords}
        enable-take-address=true, indirect-api=false, port=NvM_RpNotifyJobEnd_Can_ServerNvBlockNeed_AbnormalWakeupSleepRecords
        {enable-take-address=true, indirect-api=false, port-defined-argument-value{value=64, value-type=NvM_BlockIdType}, port=PS_Can_ServerNvBlockNeed_ActiveWUCounter}
        {enable-take-address=true, indirect-api=false, port-defined-argument-value{value=64, value-type=NvM_BlockIdType}, port=PAdmin_Can_ServerNvBlockNeed_ActiveWUCounter}
        enable-take-address=true, indirect-api=false, port=NvM_RpNotifyJobEnd_Can_ServerNvBlockNeed_ActiveWUCounter
      9 x runnable:
        NvM_MainFunction
          37 x sync call, all with timeout=0:
            OpServerCallNvM_MainFunction_JobFinished_NvM_RpNotifyJobEnd_Common_NormalNvBlockNeed_Block_ODO_{1..5}: operation=NvM_RpNotifyJobEnd_Common_NormalNvBlockNeed_Block_ODO_{1..5}.JobFinished
            OpServerCallNvM_MainFunction_JobFinished_NvM_RpNotifyJobEnd_Common_NormalNvBlockNeed_Block_MaintainOdo: operation=NvM_RpNotifyJobEnd_Common_NormalNvBlockNeed_Block_MaintainOdo.JobFinished
            OpServerCallNvM_MainFunction_JobFinished_NvM_RpNotifyJobEnd_Common_NormalNvBlockNeed_Block_Trip: operation=NvM_RpNotifyJobEnd_Common_NormalNvBlockNeed_Block_Trip.JobFinished
            OpServerCallNvM_MainFunction_JobFinished_NvM_RpNotifyJobEnd_DidDataProcessNvBlockNeed_FactoryMode: operation=NvM_RpNotifyJobEnd_DidDataProcessNvBlockNeed_FactoryMode.JobFinished
            OpServerCallNvM_MainFunction_JobFinished_NvM_RpNotifyJobEnd_DidDataProcessNvBlockNeed_VIN: operation=NvM_RpNotifyJobEnd_DidDataProcessNvBlockNeed_VIN.JobFinished
            OpServerCallNvM_MainFunction_JobFinished_NvM_RpNotifyJobEnd_DidDataProcessNvBlockNeed_VehicleMode: operation=NvM_RpNotifyJobEnd_DidDataProcessNvBlockNeed_VehicleMode.JobFinished
            OpServerCallNvM_MainFunction_JobFinished_NvM_RpNotifyJobEnd_DidDataProcessNvBlockNeed_ECUlevelNetworkConfigurationData: operation=NvM_RpNotifyJobEnd_DidDataProcessNvBlockNeed_ECUlevelNetworkConfigurationData.JobFinished
            OpServerCallNvM_MainFunction_JobFinished_NvM_RpNotifyJobEnd_EOL_NvBlockNeed_0xF18C: operation=NvM_RpNotifyJobEnd_EOL_NvBlockNeed_0xF18C.JobFinished
            OpServerCallNvM_MainFunction_JobFinished_NvM_RpNotifyJobEnd_EOL_NvBlockNeed_0xF193: operation=NvM_RpNotifyJobEnd_EOL_NvBlockNeed_0xF193.JobFinished
            OpServerCallNvM_MainFunction_JobFinished_NvM_RpNotifyJobEnd_EOL_NvBlockNeed_0xF195: operation=NvM_RpNotifyJobEnd_EOL_NvBlockNeed_0xF195.JobFinished
            OpServerCallNvM_MainFunction_JobFinished_NvM_RpNotifyJobEnd_EOL_NvBlockNeed_0xFD00: operation=NvM_RpNotifyJobEnd_EOL_NvBlockNeed_0xFD00.JobFinished
            OpServerCallNvM_MainFunction_JobFinished_NvM_RpNotifyJobEnd_EOL_NvBlockNeed_0xFD19: operation=NvM_RpNotifyJobEnd_EOL_NvBlockNeed_0xFD19.JobFinished
            OpServerCallNvM_MainFunction_JobFinished_NvM_RpNotifyJobEnd_EOL_NvBlockNeed_0xFE{20..25}: operation=NvM_RpNotifyJobEnd_EOL_NvBlockNeed_0xFE{20..25}.JobFinished
            OpServerCallNvM_MainFunction_JobFinished_NvM_RpNotifyJobEnd_EOL_NvBlockNeed_0xF187: operation=NvM_RpNotifyJobEnd_EOL_NvBlockNeed_0xF187.JobFinished
            OpServerCallNvM_MainFunction_JobFinished_NvM_RpNotifyJobEnd_Common_GateWayNvBlockNeed_Block_IPC_Config_Data: operation=NvM_RpNotifyJobEnd_Common_GateWayNvBlockNeed_Block_IPC_Config_Data.JobFinished
            OpServerCallNvM_MainFunction_JobFinished_NvM_RpNotifyJobEnd_Common_GateWayNvBlockNeed_Block_IPC_CAN_Data: operation=NvM_RpNotifyJobEnd_Common_GateWayNvBlockNeed_Block_IPC_CAN_Data.JobFinished
            OpServerCallNvM_MainFunction_JobFinished_NvM_RpNotifyJobEnd_DidDataProcessNvBlockNeed_ClusterInternalConfiguration: operation=NvM_RpNotifyJobEnd_DidDataProcessNvBlockNeed_ClusterInternalConfiguration.JobFinished
            OpServerCallNvM_MainFunction_JobFinished_NvM_RpNotifyJobEnd_AMP_NvBlockNeed_LC_Calibration: operation=NvM_RpNotifyJobEnd_AMP_NvBlockNeed_LC_Calibration.JobFinished
            OpServerCallNvM_MainFunction_JobFinished_NvM_RpNotifyJobEnd_DidDataProcessNvBlockNeed_E2ESwitch: operation=NvM_RpNotifyJobEnd_DidDataProcessNvBlockNeed_E2ESwitch.JobFinished
            OpServerCallNvM_MainFunction_JobFinished_NvM_RpNotifyJobEnd_DidDataProcessNvBlockNeed_SecOcSwitch: operation=NvM_RpNotifyJobEnd_DidDataProcessNvBlockNeed_SecOcSwitch.JobFinished
            OpServerCallNvM_MainFunction_JobFinished_NvM_RpNotifyJobEnd_NvMBlockDescriptor_Fvm_TripCount: operation=NvM_RpNotifyJobEnd_NvMBlockDescriptor_Fvm_TripCount.JobFinished
            OpServerCallNvM_MainFunction_JobFinished_NvM_RpNotifyJobEnd_Common_NormalNvBlockNeed_Menu: operation=NvM_RpNotifyJobEnd_Common_NormalNvBlockNeed_Menu.JobFinished
            OpServerCallNvM_MainFunction_JobFinished_NvM_RpNotifyJobEnd_DidDataProcessNvBlockNeed_VehicleSoftwareVersion: operation=NvM_RpNotifyJobEnd_DidDataProcessNvBlockNeed_VehicleSoftwareVersion.JobFinished
            OpServerCallNvM_MainFunction_JobFinished_NvM_RpNotifyJobEnd_AMP_NvBlockNeed_LC_Calibration2: operation=NvM_RpNotifyJobEnd_AMP_NvBlockNeed_LC_Calibration2.JobFinished
            OpServerCallNvM_MainFunction_JobFinished_NvM_RpNotifyJobEnd_SOCManagerNvBlockNeed_HealthSwitch: operation=NvM_RpNotifyJobEnd_SOCManagerNvBlockNeed_HealthSwitch.JobFinished
            OpServerCallNvM_MainFunction_JobFinished_NvM_RpNotifyJobEnd_DidDataProcessNvBlockNeed_ClusterDisplayHMIAdjustmentOffset: operation=NvM_RpNotifyJobEnd_DidDataProcessNvBlockNeed_ClusterDisplayHMIAdjustmentOffset.JobFinished
            OpServerCallNvM_MainFunction_JobFinished_NvM_RpNotifyJobEnd_Can_ServerNvBlockNeed_AbnormalWakeupSleepRecords: operation=NvM_RpNotifyJobEnd_Can_ServerNvBlockNeed_AbnormalWakeupSleepRecords.JobFinished
            OpServerCallNvM_MainFunction_JobFinished_NvM_RpNotifyJobEnd_Can_ServerNvBlockNeed_ActiveWUCounter: operation=NvM_RpNotifyJobEnd_Can_ServerNvBlockNeed_ActiveWUCounter.JobFinished
        GetErrorStatus: can-be-invoked-concurrently=true, symbol=NvM_GetErrorStatus
        SetRamBlockStatus: can-be-invoked-concurrently=true, symbol=NvM_SetRamBlockStatus
        ReadBlock: can-be-invoked-concurrently=true, symbol=NvM_ReadBlock
        WriteBlock: can-be-invoked-concurrently=true, symbol=NvM_WriteBlock
        RestoreBlockDefaults: can-be-invoked-concurrently=true, symbol=NvM_RestoreBlockDefaults
        InvalidateNvBlock: can-be-invoked-concurrently=true, symbol=NvM_InvalidateNvBlock
        EraseBlock: can-be-invoked-concurrently=true, symbol=NvM_EraseNvBlock
        SetBlockProtection: can-be-invoked-concurrently=true, symbol=NvM_SetBlockProtection
  swc implementation NvMImplementation: programming-language=C, behavior=NvMInternalBehavior
